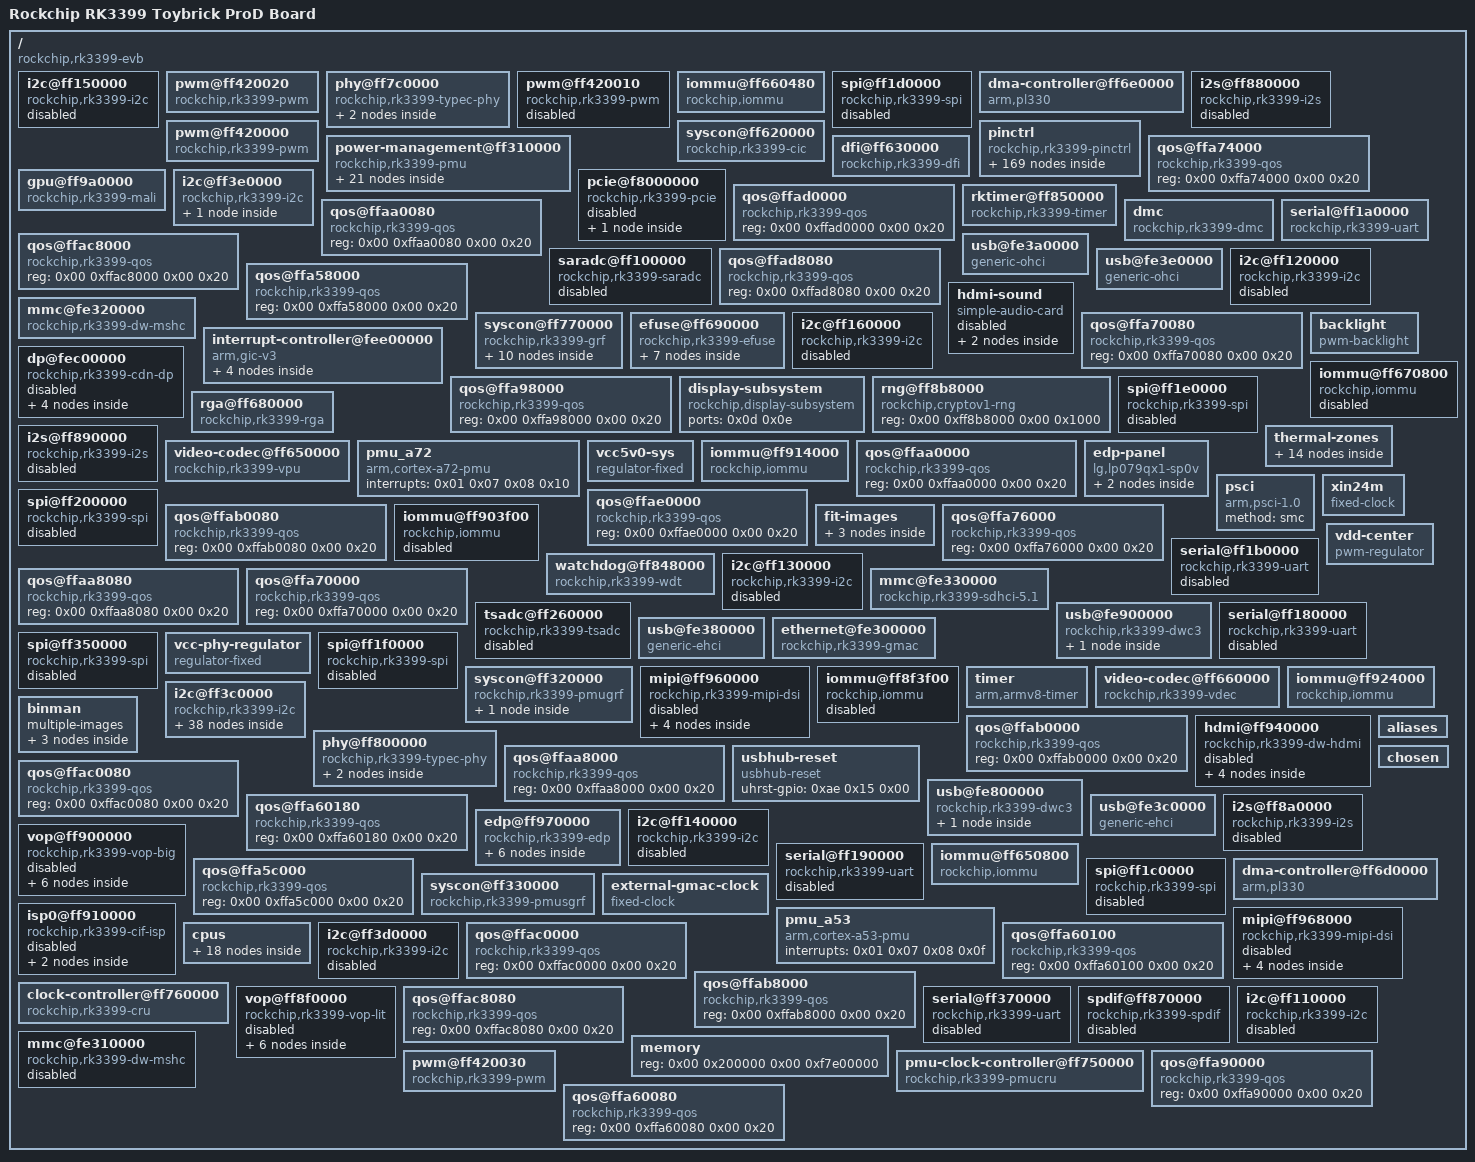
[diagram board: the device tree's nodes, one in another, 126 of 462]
/dts-v1/;

/ {
	#address-cells = <0x02>;
	model = "Rockchip RK3399 Toybrick ProD Board";
	#size-cells = <0x02>;
	interrupt-parent = <0x01>;
	compatible = "rockchip,rk3399-evb\0rockchip,rk3399";

	i2c@ff150000 {
		pinctrl-names = "default";
		#address-cells = <0x01>;
		pinctrl-0 = <0x32>;
		clock-names = "i2c\0pclk";
		assigned-clocks = <0x08 0x45>;
		assigned-clock-rates = <0xbebc200>;
		interrupts = <0x00 0x25 0x04 0x00>;
		clocks = <0x08 0x45 0x08 0x159>;
		#size-cells = <0x00>;
		compatible = "rockchip,rk3399-i2c";
		status = "disabled";
		reg = <0x00 0xff150000 0x00 0x1000>;
	};

	pwm@ff420020 {
		pinctrl-names = "default";
		pinctrl-0 = <0x7d>;
		clocks = <0x6a 0x1e>;
		#pwm-cells = <0x03>;
		compatible = "rockchip,rk3399-pwm\0rockchip,rk3288-pwm";
		status = "okay";
		reg = <0x00 0xff420020 0x00 0x10>;
	};

	phy@ff7c0000 {
		power-domains = <0x16 0x08>;
		clock-names = "tcpdcore\0tcpdphy-ref";
		assigned-clocks = <0x08 0x7e>;
		assigned-clock-rates = <0x2faf080>;
		resets = <0x08 0x95 0x08 0x94 0x08 0x14c>;
		clocks = <0x08 0x7e 0x08 0x7d>;
		extcon = <0x24>;
		compatible = "rockchip,rk3399-typec-phy";
		status = "okay";
		rockchip,grf = <0x17>;
		reg = <0x00 0xff7c0000 0x00 0x40000>;
		reset-names = "uphy\0uphy-pipe\0uphy-tcphy";

		dp-port {
			#phy-cells = <0x00>;
			phandle = <0x2a>;
		};

		usb3-port {
			#phy-cells = <0x00>;
			phandle = <0x26>;
		};
	};

	pwm@ff420010 {
		pinctrl-names = "default";
		pinctrl-0 = <0x7c>;
		clocks = <0x6a 0x1e>;
		#pwm-cells = <0x03>;
		compatible = "rockchip,rk3399-pwm\0rockchip,rk3288-pwm";
		status = "disabled";
		reg = <0x00 0xff420010 0x00 0x10>;
	};

	iommu@ff660480 {
		power-domains = <0x16 0x20>;
		clock-names = "aclk\0iface";
		interrupts = <0x00 0x75 0x04 0x00>;
		clocks = <0x08 0xed 0x08 0x1ec>;
		#iommu-cells = <0x00>;
		compatible = "rockchip,iommu";
		interrupt-names = "vdec_mmu";
		reg = <0x00 0xff660480 0x00 0x40 0x00 0xff6604c0 0x00 0x40>;
		phandle = <0x80>;
	};

	spi@ff1d0000 {
		pinctrl-names = "default";
		#address-cells = <0x01>;
		pinctrl-0 = <0x3d 0x3e 0x3f 0x40>;
		clock-names = "spiclk\0apb_pclk";
		u-boot,dm-pre-reloc;
		interrupts = <0x00 0x35 0x04 0x00>;
		clocks = <0x08 0x48 0x08 0x15c>;
		#size-cells = <0x00>;
		dma-names = "tx\0rx";
		compatible = "rockchip,rk3399-spi\0rockchip,rk3066-spi";
		status = "disabled";
		reg = <0x00 0xff1d0000 0x00 0x1000>;
		dmas = <0x38 0x0c 0x38 0x0d>;
	};

	dma-controller@ff6e0000 {
		clock-names = "apb_pclk";
		interrupts = <0x00 0x07 0x04 0x00 0x00 0x08 0x04 0x00>;
		clocks = <0x08 0xd4>;
		arm,pl330-periph-burst;
		compatible = "arm,pl330\0arm,primecell";
		reg = <0x00 0xff6e0000 0x00 0x4000>;
		phandle = <0x38>;
		#dma-cells = <0x01>;
	};

	i2s@ff880000 {
		power-domains = <0x16 0x1c>;
		pinctrl-names = "default";
		pinctrl-0 = <0x85>;
		clock-names = "i2s_clk\0i2s_hclk";
		interrupts = <0x00 0x27 0x04 0x00>;
		clocks = <0x08 0x56 0x08 0x1d4>;
		dma-names = "tx\0rx";
		#sound-dai-cells = <0x00>;
		compatible = "rockchip,rk3399-i2s\0rockchip,rk3066-i2s";
		status = "disabled";
		rockchip,grf = <0x17>;
		reg = <0x00 0xff880000 0x00 0x1000>;
		dmas = <0x49 0x00 0x49 0x01>;
	};

	pwm@ff420000 {
		pinctrl-names = "default";
		pinctrl-0 = <0x7b>;
		clocks = <0x6a 0x1e>;
		#pwm-cells = <0x03>;
		compatible = "rockchip,rk3399-pwm\0rockchip,rk3288-pwm";
		status = "okay";
		reg = <0x00 0xff420000 0x00 0x10>;
		phandle = <0xa9>;
	};

	pinctrl {
		pinctrl-names = "default";
		#address-cells = <0x02>;
		pinctrl-0 = <0xa2>;
		u-boot,dm-pre-reloc;
		#size-cells = <0x02>;
		compatible = "rockchip,rk3399-pinctrl";
		rockchip,pmu = <0x81>;
		ranges;
		rockchip,grf = <0x17>;

		i2c3 {

			i2c3-xfer {
				rockchip,pins = <0x04 0x11 0x01 0xa3 0x04 0x10 0x01 0xa3>;
				phandle = <0x30>;
			};
		};

		leds-gpio {
			rockchip,pins = <0x02 0x05 0x00 0xa6 0x02 0x04 0x00 0xa6 0x02 0x03 0x00 0xa6>;
		};

		clock {

			clk-32k {
				rockchip,pins = <0x00 0x00 0x02 0xa3>;
			};
		};

		spi2 {

			spi2-clk {
				rockchip,pins = <0x02 0x0b 0x01 0xa6>;
				phandle = <0x41>;
			};

			spi2-cs0 {
				rockchip,pins = <0x02 0x0c 0x01 0xa6>;
				phandle = <0x44>;
			};

			spi2-tx {
				rockchip,pins = <0x02 0x0a 0x01 0xa6>;
				phandle = <0x42>;
			};

			spi2-rx {
				rockchip,pins = <0x02 0x09 0x01 0xa6>;
				phandle = <0x43>;
			};
		};

		pcfg-pull-none-12ma {
			drive-strength = <0x0c>;
			bias-disable;
			phandle = <0xa5>;
		};

		pcfg-pull-up-20ma {
			drive-strength = <0x14>;
			bias-pull-up;
		};

		i2s1 {

			i2s1-2ch-bus {
				rockchip,pins = <0x04 0x03 0x01 0xa3 0x04 0x04 0x01 0xa3 0x04 0x05 0x01 0xa3 0x04 0x06 0x01 0xa3 0x04 0x07 0x01 0xa3>;
				phandle = <0x86>;
			};
		};

		i2c1 {

			i2c1-xfer {
				rockchip,pins = <0x04 0x02 0x01 0xa3 0x04 0x01 0x01 0xa3>;
				phandle = <0x2e>;
			};
		};

		gmac {

			rmii-pins {
				rockchip,pins = <0x03 0x0d 0x01 0xa3 0x03 0x0c 0x01 0xa4 0x03 0x0b 0x01 0xa3 0x03 0x0a 0x01 0xa3 0x03 0x09 0x01 0xa3 0x03 0x08 0x01 0xa3 0x03 0x07 0x01 0xa3 0x03 0x06 0x01 0xa3 0x03 0x05 0x01 0xa4 0x03 0x04 0x01 0xa4>;
			};

			rgmii-pins {
				rockchip,pins = <0x03 0x11 0x01 0xa4 0x03 0x0e 0x01 0xa3 0x03 0x0d 0x01 0xa3 0x03 0x0c 0x01 0xa4 0x03 0x0b 0x01 0xa3 0x03 0x09 0x01 0xa3 0x03 0x08 0x01 0xa3 0x03 0x07 0x01 0xa3 0x03 0x06 0x01 0xa3 0x03 0x05 0x01 0xa4 0x03 0x04 0x01 0xa4 0x03 0x03 0x01 0xa3 0x03 0x02 0x01 0xa3 0x03 0x01 0x01 0xa4 0x03 0x00 0x01 0xa4>;
				phandle = <0x1a>;
			};
		};

		usb3 {

			hub-rst {
				rockchip,pins = <0x04 0x15 0x00 0xa6>;
			};

			usb3-host-en {
				rockchip,pins = <0x02 0x02 0x00 0xa6>;
				phandle = <0x27>;
			};
		};

		spi0 {

			spi0-tx {
				rockchip,pins = <0x03 0x05 0x02 0xa6>;
				phandle = <0x3a>;
			};

			spi0-rx {
				rockchip,pins = <0x03 0x04 0x02 0xa6>;
				phandle = <0x3b>;
			};

			spi0-cs1 {
				rockchip,pins = <0x03 0x08 0x02 0xa6>;
			};

			spi0-clk {
				rockchip,pins = <0x03 0x06 0x02 0xa6>;
				phandle = <0x39>;
			};

			spi0-cs0 {
				rockchip,pins = <0x03 0x07 0x02 0xa6>;
				phandle = <0x3c>;
			};
		};

		gpio4@ff790000 {
			gpio-controller;
			interrupts = <0x00 0x12 0x04 0x00>;
			clocks = <0x08 0x152>;
			compatible = "rockchip,gpio-bank";
			#interrupt-cells = <0x02>;
			reg = <0x00 0xff790000 0x00 0x100>;
			phandle = <0xae>;
			#gpio-cells = <0x02>;
			interrupt-controller;
		};

		pcfg-pull-down-4ma {
			drive-strength = <0x04>;
			bias-pull-down;
		};

		pcfg-pull-down {
			bias-pull-down;
			phandle = <0xa7>;
		};

		uart4 {

			uart4-xfer {
				rockchip,pins = <0x01 0x07 0x01 0xa6 0x01 0x08 0x01 0xa3>;
				phandle = <0x6f>;
			};
		};

		pcfg-pull-none-18ma {
			drive-strength = <0x12>;
			bias-disable;
		};

		i2c8 {

			i2c8-xfer {
				rockchip,pins = <0x01 0x15 0x01 0xa3 0x01 0x14 0x01 0xa3>;
				phandle = <0x79>;
			};
		};

		pcfg-pull-none-20ma {
			drive-strength = <0x14>;
			bias-disable;
		};

		i2c6 {

			i2c6-xfer {
				rockchip,pins = <0x02 0x0a 0x02 0xa3 0x02 0x09 0x02 0xa3>;
				phandle = <0x32>;
			};
		};

		uarthdcp {

			uarthdcp-xfer {
				rockchip,pins = <0x04 0x15 0x02 0xa6 0x04 0x16 0x02 0xa3>;
			};
		};

		pwm1 {

			pwm1-pin {
				rockchip,pins = <0x04 0x16 0x01 0xa3>;
				phandle = <0x7c>;
			};

			pwm1-pin-pull-down {
				rockchip,pins = <0x04 0x16 0x01 0xa7>;
			};
		};

		uart2b {

			uart2b-xfer {
				rockchip,pins = <0x04 0x10 0x02 0xa6 0x04 0x11 0x02 0xa3>;
			};
		};

		edp {

			edp-hpd {
				rockchip,pins = <0x04 0x17 0x02 0xa3>;
				phandle = <0x9d>;
			};
		};

		spi5 {

			spi5-cs0 {
				rockchip,pins = <0x02 0x17 0x02 0xa6>;
				phandle = <0x4d>;
			};

			spi5-tx {
				rockchip,pins = <0x02 0x15 0x02 0xa6>;
				phandle = <0x4b>;
			};

			spi5-rx {
				rockchip,pins = <0x02 0x14 0x02 0xa6>;
				phandle = <0x4c>;
			};

			spi5-clk {
				rockchip,pins = <0x02 0x16 0x02 0xa6>;
				phandle = <0x4a>;
			};
		};

		tsadc {

			otp-pin {
				rockchip,pins = <0x01 0x06 0x00 0xa3>;
				phandle = <0x53>;
			};

			otp-out {
				rockchip,pins = <0x01 0x06 0x01 0xa3>;
				phandle = <0x54>;
			};
		};

		uart0 {

			uart0-cts {
				rockchip,pins = <0x02 0x12 0x01 0xa3>;
			};

			uart0-rts {
				rockchip,pins = <0x02 0x13 0x01 0xa3>;
			};

			uart0-xfer {
				rockchip,pins = <0x02 0x10 0x01 0xa6 0x02 0x11 0x01 0xa3>;
				phandle = <0x34>;
			};
		};

		i2c4 {

			i2c4-xfer {
				rockchip,pins = <0x01 0x0c 0x01 0xa3 0x01 0x0b 0x01 0xa3>;
				phandle = <0x78>;
			};
		};

		pcfg-pull-down-12ma {
			drive-strength = <0x0c>;
			bias-pull-down;
		};

		gpio2@ff780000 {
			gpio-controller;
			interrupts = <0x00 0x10 0x04 0x00>;
			clocks = <0x08 0x150>;
			compatible = "rockchip,gpio-bank";
			#interrupt-cells = <0x02>;
			reg = <0x00 0xff780000 0x00 0x100>;
			#gpio-cells = <0x02>;
			interrupt-controller;
		};

		spdif {

			spdif-bus-1 {
				rockchip,pins = <0x03 0x10 0x03 0xa3>;
			};

			spdif-bus {
				rockchip,pins = <0x04 0x15 0x01 0xa3>;
				phandle = <0x84>;
			};
		};

		gpio0@ff720000 {
			gpio-controller;
			interrupts = <0x00 0x0e 0x04 0x00>;
			clocks = <0x6a 0x17>;
			compatible = "rockchip,gpio-bank";
			#interrupt-cells = <0x02>;
			reg = <0x00 0xff720000 0x00 0x100>;
			phandle = <0x1b>;
			#gpio-cells = <0x02>;
			interrupt-controller;
		};

		pcfg-output-high {
			output-high;
		};

		pcie {

			pci-clkreqn-cpm {
				rockchip,pins = <0x02 0x1a 0x00 0xa3>;
				phandle = <0x15>;
			};

			pci-clkreqnb-cpm {
				rockchip,pins = <0x04 0x18 0x00 0xa3>;
			};
		};

		pcfg-pull-up {
			phandle = <0xa6>;
			bias-pull-up;
		};

		spi3 {

			spi3-tx {
				rockchip,pins = <0x01 0x10 0x01 0xa6>;
				phandle = <0x6c>;
			};

			spi3-rx {
				rockchip,pins = <0x01 0x0f 0x01 0xa6>;
				phandle = <0x6d>;
			};

			spi3-clk {
				rockchip,pins = <0x01 0x11 0x01 0xa6>;
				phandle = <0x6b>;
			};

			spi3-cs0 {
				rockchip,pins = <0x01 0x12 0x01 0xa6>;
				phandle = <0x6e>;
			};
		};

		pwm3a {

			pwm3a-pin {
				rockchip,pins = <0x00 0x06 0x01 0xa3>;
				phandle = <0x7e>;
			};
		};

		sdio0 {

			sdio0-clk {
				rockchip,pins = <0x02 0x19 0x01 0xa3>;
			};

			sdio0-wp {
				rockchip,pins = <0x00 0x03 0x01 0xa6>;
			};

			sdio0-bus4 {
				rockchip,pins = <0x02 0x14 0x01 0xa6 0x02 0x15 0x01 0xa6 0x02 0x16 0x01 0xa6 0x02 0x17 0x01 0xa6>;
			};

			sdio0-bkpwr {
				rockchip,pins = <0x02 0x1c 0x01 0xa6>;
			};

			sdio0-cd {
				rockchip,pins = <0x02 0x1a 0x01 0xa6>;
			};

			sdio0-pwr {
				rockchip,pins = <0x02 0x1b 0x01 0xa6>;
			};

			sdio0-int {
				rockchip,pins = <0x00 0x04 0x01 0xa6>;
			};

			sdio0-bus1 {
				rockchip,pins = <0x02 0x14 0x01 0xa6>;
			};

			sdio0-cmd {
				rockchip,pins = <0x02 0x18 0x01 0xa6>;
			};
		};

		pcfg-pull-up-2ma {
			drive-strength = <0x02>;
			bias-pull-up;
		};

		i2c2 {

			i2c2-xfer {
				rockchip,pins = <0x02 0x01 0x02 0xa5 0x02 0x00 0x02 0xa5>;
				phandle = <0x2f>;
			};
		};

		pmic {

			soc-slppin-slp {
				rockchip,pins = <0x01 0x05 0x01 0xa7>;
			};

			vsel2-gpio {
				rockchip,pins = <0x01 0x0e 0x00 0xa7>;
				phandle = <0x77>;
			};

			vsel1-gpio {
				rockchip,pins = <0x01 0x11 0x00 0xa7>;
				phandle = <0x76>;
			};

			soc-slppin-gpio {
				rockchip,pins = <0x01 0x05 0x00 0xa8>;
			};

			pmic-int-l {
				rockchip,pins = <0x01 0x12 0x00 0xa6>;
				phandle = <0x72>;
			};
		};

		pcfg-pull-none {
			bias-disable;
			phandle = <0xa3>;
		};

		spi1 {

			spi1-cs0 {
				rockchip,pins = <0x01 0x0a 0x02 0xa6>;
				phandle = <0x40>;
			};

			spi1-clk {
				rockchip,pins = <0x01 0x09 0x02 0xa6>;
				phandle = <0x3d>;
			};

			spi1-tx {
				rockchip,pins = <0x01 0x08 0x02 0xa6>;
				phandle = <0x3e>;
			};

			spi1-rx {
				rockchip,pins = <0x01 0x07 0x02 0xa6>;
				phandle = <0x3f>;
			};
		};

		pcfg-pull-down-18ma {
			drive-strength = <0x12>;
			bias-pull-down;
		};

		sdmmc {

			sdmmc-wp {
				rockchip,pins = <0x00 0x08 0x01 0xa6>;
			};

			sdmmc-bus1 {
				rockchip,pins = <0x04 0x08 0x01 0xa6>;
			};

			sdmmc-cd {
				rockchip,pins = <0x00 0x07 0x01 0xa6>;
			};

			sdmmc-bus4 {
				rockchip,pins = <0x04 0x08 0x01 0xa6 0x04 0x09 0x01 0xa6 0x04 0x0a 0x01 0xa6 0x04 0x0b 0x01 0xa6>;
				phandle = <0x1e>;
			};

			sdmmc-cmd {
				rockchip,pins = <0x04 0x0d 0x01 0xa6>;
				phandle = <0x1d>;
			};

			sdmmc-clk {
				rockchip,pins = <0x04 0x0c 0x01 0xa3>;
				phandle = <0x1c>;
			};
		};

		i2s0 {

			i2s0-8ch-bus {
				rockchip,pins = <0x03 0x18 0x01 0xa3 0x03 0x19 0x01 0xa3 0x03 0x1a 0x01 0xa3 0x03 0x1b 0x01 0xa3 0x03 0x1c 0x01 0xa3 0x03 0x1d 0x01 0xa3 0x03 0x1e 0x01 0xa3 0x03 0x1f 0x01 0xa3 0x04 0x00 0x01 0xa3>;
				phandle = <0x85>;
			};

			i2s0-2ch-bus {
				rockchip,pins = <0x03 0x18 0x01 0xa3 0x03 0x19 0x01 0xa3 0x03 0x1a 0x01 0xa3 0x03 0x1b 0x01 0xa3 0x03 0x1f 0x01 0xa3 0x04 0x00 0x01 0xa3>;
			};
		};

		i2c0 {

			i2c0-xfer {
				rockchip,pins = <0x01 0x0f 0x02 0xa3 0x01 0x10 0x02 0xa3>;
				phandle = <0x70>;
			};
		};

		suspend {

			ap-pwroff {
				rockchip,pins = <0x01 0x05 0x01 0xa3>;
			};

			ddrio-pwroff {
				rockchip,pins = <0x00 0x01 0x01 0xa3>;
			};
		};

		testclk {

			test-clkout2 {
				rockchip,pins = <0x00 0x08 0x03 0xa3>;
			};

			test-clkout0 {
				rockchip,pins = <0x00 0x00 0x01 0xa3>;
			};

			test-clkout1 {
				rockchip,pins = <0x02 0x19 0x02 0xa3>;
			};
		};

		pcfg-pull-up-8ma {
			drive-strength = <0x08>;
			bias-pull-up;
		};

		pcfg-pull-down-20ma {
			drive-strength = <0x14>;
			bias-pull-down;
		};

		npu_clk {

			npu-ref-clk {
				rockchip,pins = <0x00 0x02 0x01 0xa3>;
				phandle = <0xa2>;
			};
		};

		pcfg-pull-none-13ma {
			drive-strength = <0x0d>;
			bias-disable;
			phandle = <0xa4>;
		};

		fusb30x {

			fusb0-int {
				rockchip,pins = <0x01 0x02 0x00 0xa6>;
				phandle = <0x7a>;
			};
		};

		uart3 {

			uart3-cts {
				rockchip,pins = <0x03 0x10 0x02 0xa3>;
			};

			uart3-rts {
				rockchip,pins = <0x03 0x11 0x02 0xa3>;
			};

			uart3-xfer {
				rockchip,pins = <0x03 0x0e 0x02 0xa6 0x03 0x0f 0x02 0xa3>;
				phandle = <0x37>;
			};
		};

		pcfg-output-low {
			phandle = <0xa8>;
			output-low;
		};

		i2c7 {

			i2c7-xfer {
				rockchip,pins = <0x02 0x08 0x02 0xa3 0x02 0x07 0x02 0xa3>;
				phandle = <0x33>;
			};
		};

		pwm2 {

			pwm2-pin {
				rockchip,pins = <0x01 0x13 0x01 0xa3>;
				phandle = <0x7d>;
			};

			pwm2-pin-pull-down {
				rockchip,pins = <0x01 0x13 0x01 0xa7>;
			};
		};

		uart2c {

			uart2c-xfer {
				rockchip,pins = <0x04 0x13 0x01 0xa6 0x04 0x14 0x01 0xa3>;
				phandle = <0x36>;
			};
		};

		uart1 {

			uart1-xfer {
				rockchip,pins = <0x03 0x0c 0x02 0xa6 0x03 0x0d 0x02 0xa3>;
				phandle = <0x35>;
			};
		};

		hdmi {

			hdmi-i2c-xfer {
				rockchip,pins = <0x04 0x11 0x03 0xa3 0x04 0x10 0x03 0xa3>;
			};

			hdmi-cec {
				rockchip,pins = <0x04 0x17 0x01 0xa3>;
			};
		};

		i2c5 {

			i2c5-xfer {
				rockchip,pins = <0x03 0x0b 0x02 0xa3 0x03 0x0a 0x02 0xa3>;
				phandle = <0x31>;
			};
		};

		pwm0 {

			pwm0-pin-pull-down {
				rockchip,pins = <0x04 0x12 0x01 0xa7>;
			};

			vop1-pwm-pin {
				rockchip,pins = <0x04 0x12 0x03 0xa3>;
			};

			vop0-pwm-pin {
				rockchip,pins = <0x04 0x12 0x02 0xa3>;
			};

			pwm0-pin {
				rockchip,pins = <0x04 0x12 0x01 0xa3>;
				phandle = <0x7b>;
			};
		};

		uart2a {

			uart2a-xfer {
				rockchip,pins = <0x04 0x08 0x02 0xa6 0x04 0x09 0x02 0xa3>;
			};
		};

		spi4 {

			spi4-clk {
				rockchip,pins = <0x03 0x02 0x02 0xa6>;
				phandle = <0x45>;
			};

			spi4-tx {
				rockchip,pins = <0x03 0x01 0x02 0xa6>;
				phandle = <0x46>;
			};

			spi4-rx {
				rockchip,pins = <0x03 0x00 0x02 0xa6>;
				phandle = <0x47>;
			};

			spi4-cs0 {
				rockchip,pins = <0x03 0x03 0x02 0xa6>;
				phandle = <0x48>;
			};
		};

		pcfg-pull-down-8ma {
			drive-strength = <0x08>;
			bias-pull-down;
		};

		gpio1@ff730000 {
			gpio-controller;
			interrupts = <0x00 0x0f 0x04 0x00>;
			clocks = <0x6a 0x18>;
			compatible = "rockchip,gpio-bank";
			#interrupt-cells = <0x02>;
			reg = <0x00 0xff730000 0x00 0x100>;
			phandle = <0x71>;
			#gpio-cells = <0x02>;
			interrupt-controller;
		};

		pwm3b {

			pwm3b-pin {
				rockchip,pins = <0x01 0x0e 0x01 0xa3>;
			};
		};

		gpio3@ff788000 {
			gpio-controller;
			interrupts = <0x00 0x11 0x04 0x00>;
			clocks = <0x08 0x151>;
			compatible = "rockchip,gpio-bank";
			#interrupt-cells = <0x02>;
			reg = <0x00 0xff788000 0x00 0x100>;
			phandle = <0x14>;
			#gpio-cells = <0x02>;
			interrupt-controller;
		};

		pcfg-pull-up-18ma {
			drive-strength = <0x12>;
			bias-pull-up;
		};
	};

	power-management@ff310000 {
		u-boot,dm-pre-reloc;
		compatible = "rockchip,rk3399-pmu\0syscon\0simple-mfd";
		reg = <0x00 0xff310000 0x00 0x1000>;

		power-controller {
			#address-cells = <0x01>;
			#size-cells = <0x00>;
			#power-domain-cells = <0x01>;
			compatible = "rockchip,rk3399-power-controller";
			phandle = <0x16>;

			power-domain@9 {
				clocks = <0x08 0x80 0x08 0x7f>;
				#power-domain-cells = <0x00>;
				reg = <0x09>;
			};

			power-domain@27 {
				clocks = <0x08 0x1ce 0x08 0x4c>;
				#power-domain-cells = <0x00>;
				reg = <0x1b>;
				pm_qos = <0x5e>;
			};

			power-domain@35 {
				clocks = <0x08 0xd0>;
				#power-domain-cells = <0x00>;
				reg = <0x23>;
				pm_qos = <0x5b>;
			};

			power-domain@25 {
				clocks = <0x08 0x16c>;
				#power-domain-cells = <0x00>;
				reg = <0x19>;
			};

			power-domain@15 {
				#address-cells = <0x01>;
				#size-cells = <0x00>;
				#power-domain-cells = <0x01>;
				reg = <0x0f>;

				power-domain@19 {
					clocks = <0x08 0xe5 0x08 0x1df>;
					#power-domain-cells = <0x00>;
					reg = <0x13>;
					pm_qos = <0x63 0x64>;
				};

				power-domain@21 {
					clocks = <0x08 0xde 0x08 0x1e7 0x08 0x172>;
					#power-domain-cells = <0x00>;
					reg = <0x15>;
					pm_qos = <0x62>;
				};

				power-domain@16 {
					#address-cells = <0x01>;
					#size-cells = <0x00>;
					#power-domain-cells = <0x01>;
					reg = <0x10>;

					power-domain@17 {
						clocks = <0x08 0xd9 0x08 0x1d9>;
						#power-domain-cells = <0x00>;
						reg = <0x11>;
						pm_qos = <0x67 0x68>;
					};

					power-domain@18 {
						clocks = <0x08 0xdb 0x08 0x1db>;
						#power-domain-cells = <0x00>;
						reg = <0x12>;
						pm_qos = <0x69>;
					};
				};

				power-domain@20 {
					clocks = <0x08 0xe6 0x08 0x1e0>;
					#power-domain-cells = <0x00>;
					reg = <0x14>;
					pm_qos = <0x65 0x66>;
				};
			};

			power-domain@33 {
				clocks = <0x08 0xdc 0x08 0x1e5>;
				#power-domain-cells = <0x00>;
				reg = <0x21>;
				pm_qos = <0x56 0x57>;
			};

			power-domain@23 {
				clocks = <0x08 0xf0>;
				#power-domain-cells = <0x00>;
				reg = <0x17>;
				pm_qos = <0x5c>;
			};

			power-domain@31 {
				clocks = <0x08 0xeb 0x08 0x1ea>;
				#power-domain-cells = <0x00>;
				reg = <0x1f>;
				pm_qos = <0x58>;
			};

			power-domain@28 {
				clocks = <0x08 0x1ee>;
				#power-domain-cells = <0x00>;
				reg = <0x1c>;
				pm_qos = <0x5f>;
			};

			power-domain@8 {
				clocks = <0x08 0x7e 0x08 0x7d>;
				#power-domain-cells = <0x00>;
				reg = <0x08>;
			};

			power-domain@34 {
				clocks = <0x08 0xe1 0x08 0x1dd>;
				#power-domain-cells = <0x00>;
				reg = <0x22>;
				pm_qos = <0x55>;
			};

			power-domain@24 {
				clocks = <0x08 0xf4>;
				#power-domain-cells = <0x00>;
				reg = <0x18>;
				pm_qos = <0x60 0x61>;
			};

			power-domain@32 {
				clocks = <0x08 0xed 0x08 0x1ec>;
				#power-domain-cells = <0x00>;
				reg = <0x20>;
				pm_qos = <0x59 0x5a>;
			};

			power-domain@22 {
				clocks = <0x08 0xd5 0x08 0x166>;
				#power-domain-cells = <0x00>;
				reg = <0x16>;
				pm_qos = <0x5d>;
			};
		};
	};

	syscon@ff620000 {
		u-boot,dm-pre-reloc;
		compatible = "rockchip,rk3399-cic\0syscon";
		reg = <0x00 0xff620000 0x00 0x100>;
	};

	qos@ffa74000 {
		compatible = "rockchip,rk3399-qos\0syscon";
		reg = <0x00 0xffa74000 0x00 0x20>;
		phandle = <0x5e>;
	};

	gpu@ff9a0000 {
		power-domains = <0x16 0x23>;
		mali-supply = <0xa1>;
		interrupts = <0x00 0x14 0x04 0x00 0x00 0x15 0x04 0x00 0x00 0x13 0x04 0x00>;
		clocks = <0x08 0xd0>;
		compatible = "rockchip,rk3399-mali\0arm,mali-t860";
		status = "okay";
		interrupt-names = "job\0mmu\0gpu";
		reg = <0x00 0xff9a0000 0x00 0x10000>;
		phandle = <0x52>;
		#cooling-cells = <0x02>;
	};

	dfi@ff630000 {
		clock-names = "pclk_ddr_mon";
		u-boot,dm-pre-reloc;
		clocks = <0x08 0x179>;
		compatible = "rockchip,rk3399-dfi";
		rockchip,pmu = <0x81>;
		reg = <0x00 0xff630000 0x00 0x4000>;
		phandle = <0xaf>;
	};

	i2c@ff3e0000 {
		pinctrl-names = "default";
		#address-cells = <0x01>;
		pinctrl-0 = <0x79>;
		clock-names = "i2c\0pclk";
		assigned-clocks = <0x6a 0x0b>;
		i2c-scl-rising-time-ns = <0x159>;
		i2c-scl-falling-time-ns = <0x0b>;
		assigned-clock-rates = <0xbebc200>;
		interrupts = <0x00 0x3a 0x04 0x00>;
		clocks = <0x6a 0x0b 0x6a 0x1d>;
		#size-cells = <0x00>;
		clock-frequency = <0x186a0>;
		compatible = "rockchip,rk3399-i2c";
		status = "okay";
		reg = <0x00 0xff3e0000 0x00 0x1000>;

		fusb30x@22 {
			pinctrl-names = "default";
			pinctrl-0 = <0x7a>;
			int-n-gpios = <0x71 0x02 0x00>;
			vbus-5v-gpios = <0x1b 0x01 0x01>;
			compatible = "fairchild,fusb302";
			status = "okay";
			reg = <0x22>;
			phandle = <0x24>;
		};
	};

	pcie@f8000000 {
		pinctrl-names = "default";
		#address-cells = <0x03>;
		phy-names = "pcie-phy-0\0pcie-phy-1\0pcie-phy-2\0pcie-phy-3";
		bus-range = <0x00 0x1f>;
		pinctrl-0 = <0x15>;
		clock-names = "aclk\0aclk-perf\0hclk\0pm";
		reg-names = "axi-base\0apb-base";
		ep-gpios = <0x14 0x0d 0x00>;
		resets = <0x08 0x82 0x08 0x83 0x08 0x84 0x08 0x85 0x08 0x86 0x08 0x81 0x08 0x80>;
		interrupts = <0x00 0x31 0x04 0x00 0x00 0x32 0x04 0x00 0x00 0x33 0x04 0x00>;
		clocks = <0x08 0xc5 0x08 0xc4 0x08 0x147 0x08 0xa0>;
		interrupt-map = <0x00 0x00 0x00 0x01 0x11 0x00 0x00 0x00 0x00 0x02 0x11 0x01 0x00 0x00 0x00 0x03 0x11 0x02 0x00 0x00 0x00 0x04 0x11 0x03>;
		#size-cells = <0x02>;
		aspm-no-l0s;
		max-link-speed = <0x01>;
		device_type = "pci";
		interrupt-map-mask = <0x00 0x00 0x00 0x07>;
		num-lanes = <0x04>;
		compatible = "rockchip,rk3399-pcie";
		ranges = <0x82000000 0x00 0xfa000000 0x00 0xfa000000 0x00 0x1e00000 0x81000000 0x00 0xfbe00000 0x00 0xfbe00000 0x00 0x100000>;
		msi-map = <0x00 0x12 0x00 0x1000>;
		#interrupt-cells = <0x01>;
		status = "disabled";
		interrupt-names = "sys\0legacy\0client";
		phys = <0x13 0x00 0x13 0x01 0x13 0x02 0x13 0x03>;
		reg = <0x00 0xf8000000 0x00 0x2000000 0x00 0xfd000000 0x00 0x1000000>;
		reset-names = "core\0mgmt\0mgmt-sticky\0pipe\0pm\0pclk\0aclk";

		interrupt-controller {
			#address-cells = <0x00>;
			#interrupt-cells = <0x01>;
			phandle = <0x11>;
			interrupt-controller;
		};
	};

	qos@ffad0000 {
		compatible = "rockchip,rk3399-qos\0syscon";
		reg = <0x00 0xffad0000 0x00 0x20>;
		phandle = <0x69>;
	};

	rktimer@ff850000 {
		clock-names = "pclk\0timer";
		interrupts = <0x00 0x51 0x04 0x00>;
		clocks = <0x08 0x168 0x08 0x5a>;
		compatible = "rockchip,rk3399-timer";
		reg = <0x00 0xff850000 0x00 0x1000>;
	};

	qos@ffaa0080 {
		compatible = "rockchip,rk3399-qos\0syscon";
		reg = <0x00 0xffaa0080 0x00 0x20>;
		phandle = <0x64>;
	};

	dmc {
		clock-names = "dmc_clk";
		u-boot,dm-pre-reloc;
		interrupts = <0x00 0x01 0x04 0x00>;
		clocks = <0x08 0xaa>;
		devfreq-events = <0xaf>;
		compatible = "rockchip,rk3399-dmc";
		rockchip,sdram-params = <0x02 0x0a 0x03 0x02 0x02 0x00 0x0f 0x0f 0x0f 0x0f 0x01 0x1d191519 0x14040808 0x02 0x6226 0x54 0x00 0x02 0x0a 0x03 0x02 0x02 0x00 0x0f 0x0f 0x0f 0x0f 0x01 0x1d191519 0x14040808 0x02 0x6226 0x54 0x00 0x320 0x06 0x02 0x0d 0x01 0x700 0x00 0x00 0x00 0x00 0x50 0x27100 0x320 0x1f40 0x50 0x27100 0x320 0x1f40 0x50 0x27100 0x320 0x1001f40 0x00 0x101 0x20100 0xa0 0x190 0x00 0x6180000 0x61800 0x4000618 0x33080004 0x280f0622 0x22330800 0x280f06 0x6223308 0x600280f 0xa0a 0x600dac0 0xa0a060c 0x600dac0 0xa0a060c 0x600dac0 0x203000c 0xf0c0f00 0x40c0f0c 0x14000a0a 0x3030a0a 0x10003 0x31b1b1b 0x111111 0x00 0x3010000 0xc2800a8 0xc2800a8 0xc2800a8 0x00 0x60006 0x140006 0x140014 0xf0f0f 0x00 0x00 0x00 0xb00000 0xb000b0 0xb000b0 0xb0 0x00 0x00 0x00 0x00 0x00 0x00 0x301 0x01 0x00 0x00 0x1000000 0x80104002 0x40003 0x40005 0x30000 0x50004 0x04 0x40003 0x40005 0x30a00000 0x1850 0x185030a0 0x30a00000 0x1850 0x00 0x00 0x00 0x00 0x00 0x2020200 0x20202 0x30200 0x40700 0x302 0x2000407 0x03 0x30f04 0x70004 0x00 0x00 0x00 0x00 0x00 0x00 0x00 0x10000 0x20040020 0x200400 0x1000400 0xb80 0x00 0x01 0x02 0x0e 0x00 0x00 0x00 0x00 0x00 0xa00000 0xc80050 0xc80000 0x5000a0 0xc8 0xa000c8 0xc80050 0xc80000 0x00 0x00 0x00 0x430000 0x1a 0x1a0043 0x430000 0x1a 0x10001 0x7000001 0x707 0x00 0x00 0x00 0x00 0x00 0x00 0x430000 0x1a 0x1a0043 0x430000 0x1a 0x10001 0x7000001 0x707 0x00 0x00 0x00 0x00 0x00 0x00 0x1000000 0x00 0x00 0x18151100 0x0c 0x00 0x00 0x00 0x00 0x00 0x00 0x00 0x00 0x00 0x00 0x00 0x00 0x00 0x32003 0x480120 0x00 0x1200320 0x48 0x32000 0x480120 0x00 0x280000 0x280028 0x1010100 0x1000202 0xa000002 0x1000f0f 0x00 0x00 0x10003 0xc03 0x100 0x10000 0x1000000 0x10000 0x01 0x00 0x00 0x00 0x00 0x00 0x00 0x00 0x00 0x00 0x10000 0x3030301 0x1010808 0x3030001 0xa0a0a03 0x2080808 0x2050103 0x2050103 0x50103 0x20202 0x5020500 0x20502 0x00 0x00 0xd000001 0x10028 0x10000 0x03 0x00 0x00 0x00 0x00 0x00 0x00 0x00 0x00 0x10100 0x1000000 0x01 0x303 0x00 0x00 0x00 0x00 0x00 0x00 0x00 0x00 0x00 0x00 0x00 0x00 0x00 0x00 0x00 0x556aa 0xaaaaa 0xaa955 0x55555 0xb3133 0x4cd33 0x4cecc 0xb32cc 0x10300 0x3000100 0x00 0x00 0x00 0x00 0x00 0x00 0x00 0x00 0xffff00 0x1e1e0000 0x800001e 0x1850 0x200 0x200 0x200 0x200 0x1850 0xf320 0x1850050a 0x200 0x200 0x200 0x200 0x1850 0xf320 0x1850050a 0x200 0x200 0x200 0x200 0x1850 0xf320 0x202050a 0x3030202 0x18 0x00 0x00 0x1403 0x00 0x00 0x00 0x30000 0xe0020 0xe0020 0xe0020 0x00 0x00 0x1000000 0x70007 0x50007 0x00 0x00 0x00 0x00 0x00 0x00 0x00 0x00 0x1000101 0x1010101 0x1000101 0x1000100 0x10001 0x10002 0x20100 0x02 0x700 0x00 0x30a0 0x1850 0x30a0 0x1850 0x30a0 0x18501850 0x200 0x200 0x200 0x200 0x1850 0x200 0x200 0x200 0x200 0x1850 0x200 0x200 0x200 0x200 0x10000 0x07 0x81000001 0xf0003f0 0x3fffffff 0xf0000a0 0x377ff000 0xf000020 0x377ff000 0xf000030 0x377ff000 0xf0000b0 0x377ff000 0xf000100 0x377ff000 0xf000110 0x377ff000 0xf000010 0x377ff000 0x3000101 0x42e2e2e 0x6180006 0x61800 0x18 0xc2800a8 0xc2800a8 0xc2800a8 0x500 0x00 0x00 0x00 0x00 0x00 0x00 0x00 0x00 0x4040000 0xd000004 0x128 0x00 0x30003 0x18 0x00 0x00 0x3060002 0x3010301 0x1080801 0x4020201 0x1080804 0x00 0x3030000 0xa0a0a03 0x00 0x00 0x00 0x30300 0x14 0x00 0x1010300 0x00 0x00 0x1000000 0x101 0x55555a5a 0x55555a5a 0x55555a5a 0x55555a5a 0xa0a0001 0x505000a 0x05 0x100 0x30000 0x17030000 0xe0020 0xe0020 0xe0020 0x00 0x00 0x100 0x140a0000 0xa030a 0x3000a03 0x10a000a 0x100 0x1000000 0x00 0x100 0x1e1a0000 0x10010204 0x7070705 0x20000202 0x201000 0x201000 0x4041000 0x10100100 0x10110 0x4b004a 0x1a030000 0x102041e 0x34000000 0x00 0x00 0x00 0x4300 0x1001a 0x4d4d07 0x1a0043 0x4d070001 0x434d 0x1001a 0x4d4d07 0x1a0043 0x4d070001 0x434d 0x1001a 0x4d4d07 0x1a0043 0x4d070001 0x43004d 0x1001a 0x4d4d07 0x1a0043 0x4d070001 0x434d 0x1001a 0x4d4d07 0x1a0043 0x4d070001 0x434d 0x1001a 0x4d4d07 0x1a0043 0x4d070001 0x100004d 0xc800c8 0x60400c8 0xc060f11 0x2200d890 0xa0c2005 0xf11060a 0xc06 0x2200d890 0xa0c2005 0xf11060a 0xc06 0x2200d890 0xa0c2005 0x200020a 0x2000200 0x2000200 0x2000200 0x2000200 0x00 0x00 0x00 0x00 0x00 0x00 0x00 0x00 0x00 0x00 0x00 0x00 0x1000300 0x185000 0xf320 0x1850 0xf320 0x1850 0xf320 0x8000000 0x100 0x00 0x00 0x00 0x00 0x02 0x76543210 0x4c008 0xb3 0x00 0x00 0x10000 0x1665555 0x665555 0x10f00 0x5010200 0x03 0x1700c0 0xcc0101 0x30066 0x00 0x00 0x00 0x00 0x00 0x00 0x00 0x00 0x4080000 0x4080400 0x8000000 0xc00c007 0x100 0x100 0x55555555 0xaaaaaaaa 0x55555555 0xaaaaaaaa 0x5555 0x00 0x00 0x00 0x00 0x00 0x00 0x00 0x00 0x00 0x00 0x00 0x00 0x00 0x00 0x00 0x00 0x00 0x00 0x00 0x200000 0x00 0x00 0x00 0x00 0x00 0x00 0x2700270 0x2700270 0x2700270 0x2700270 0x270 0x00 0x00 0x00 0x00 0x800000 0x800080 0x800080 0x800080 0x800080 0x800080 0x800080 0x800080 0x800080 0xb30080 0x03 0x00 0x20000 0x200 0x00 0x51315152 0xc0013150 0x20000c0 0x100001 0x7054208 0xf0c18 0x1000140 0xc20 0x00 0x00 0x00 0x00 0x00 0x00 0x00 0x00 0x00 0x00 0x00 0x00 0x00 0x00 0x00 0x00 0x00 0x00 0x00 0x00 0x00 0x00 0x00 0x00 0x00 0x00 0x00 0x00 0x00 0x00 0x00 0x00 0x00 0x00 0x00 0x00 0x00 0x76543210 0x4c008 0xb3 0x00 0x00 0x10000 0x1665555 0x665555 0x10f00 0x5010200 0x03 0x1700c0 0xcc0101 0x30066 0x00 0x00 0x00 0x00 0x00 0x00 0x00 0x00 0x4080000 0x4080400 0x8000000 0xc00c007 0x100 0x100 0x55555555 0xaaaaaaaa 0x55555555 0xaaaaaaaa 0x5555 0x00 0x00 0x00 0x00 0x00 0x00 0x00 0x00 0x00 0x00 0x00 0x00 0x00 0x00 0x00 0x00 0x00 0x00 0x00 0x200000 0x00 0x00 0x00 0x00 0x00 0x00 0x2700270 0x2700270 0x2700270 0x2700270 0x270 0x00 0x00 0x00 0x00 0x800000 0x800080 0x800080 0x800080 0x800080 0x800080 0x800080 0x800080 0x800080 0xb30080 0x03 0x00 0x20000 0x200 0x00 0x51315152 0xc0013150 0x20000c0 0x100001 0x7054208 0xf0c18 0x1000140 0xc20 0x00 0x00 0x00 0x00 0x00 0x00 0x00 0x00 0x00 0x00 0x00 0x00 0x00 0x00 0x00 0x00 0x00 0x00 0x00 0x00 0x00 0x00 0x00 0x00 0x00 0x00 0x00 0x00 0x00 0x00 0x00 0x00 0x00 0x00 0x00 0x00 0x00 0x76543210 0x4c008 0xb3 0x00 0x00 0x10000 0x1665555 0x665555 0x10f00 0x5010200 0x03 0x1700c0 0xcc0101 0x30066 0x00 0x00 0x00 0x00 0x00 0x00 0x00 0x00 0x4080000 0x4080400 0x8000000 0xc00c007 0x100 0x100 0x55555555 0xaaaaaaaa 0x55555555 0xaaaaaaaa 0x5555 0x00 0x00 0x00 0x00 0x00 0x00 0x00 0x00 0x00 0x00 0x00 0x00 0x00 0x00 0x00 0x00 0x00 0x00 0x00 0x200000 0x00 0x00 0x00 0x00 0x00 0x00 0x2700270 0x2700270 0x2700270 0x2700270 0x270 0x00 0x00 0x00 0x00 0x800000 0x800080 0x800080 0x800080 0x800080 0x800080 0x800080 0x800080 0x800080 0xb30080 0x03 0x00 0x20000 0x200 0x00 0x51315152 0xc0013150 0x20000c0 0x100001 0x7054208 0xf0c18 0x1000140 0xc20 0x00 0x00 0x00 0x00 0x00 0x00 0x00 0x00 0x00 0x00 0x00 0x00 0x00 0x00 0x00 0x00 0x00 0x00 0x00 0x00 0x00 0x00 0x00 0x00 0x00 0x00 0x00 0x00 0x00 0x00 0x00 0x00 0x00 0x00 0x00 0x00 0x00 0x76543210 0x4c008 0xb3 0x00 0x00 0x10000 0x1665555 0x665555 0x10f00 0x5010200 0x03 0x1700c0 0xcc0101 0x30066 0x00 0x00 0x00 0x00 0x00 0x00 0x00 0x00 0x4080000 0x4080400 0x8000000 0xc00c007 0x100 0x100 0x55555555 0xaaaaaaaa 0x55555555 0xaaaaaaaa 0x5555 0x00 0x00 0x00 0x00 0x00 0x00 0x00 0x00 0x00 0x00 0x00 0x00 0x00 0x00 0x00 0x00 0x00 0x00 0x00 0x200000 0x00 0x00 0x00 0x00 0x00 0x00 0x2700270 0x2700270 0x2700270 0x2700270 0x270 0x00 0x00 0x00 0x00 0x800000 0x800080 0x800080 0x800080 0x800080 0x800080 0x800080 0x800080 0x800080 0xb30080 0x03 0x00 0x20000 0x200 0x00 0x51315152 0xc0013150 0x20000c0 0x100001 0x7054208 0xf0c18 0x1000140 0xc20 0x00 0x00 0x00 0x00 0x00 0x00 0x00 0x00 0x00 0x00 0x00 0x00 0x00 0x00 0x00 0x00 0x00 0x00 0x00 0x00 0x00 0x00 0x00 0x00 0x00 0x00 0x00 0x00 0x00 0x00 0x00 0x00 0x00 0x00 0x00 0x00 0x00 0x00 0x800000 0x00 0x00 0x00 0x00 0x00 0x01 0x00 0x00 0x00 0x400320 0x40 0x806420 0x917531 0x806420 0x1917531 0x20003 0x00 0x00 0x00 0x556aa 0xaaaaa 0xaa955 0x55555 0xb3133 0x4cd33 0x4cecc 0xb32cc 0xa418820 0x103f0000 0x3f 0x38055 0x3800380 0x3800380 0x380 0x42080010 0x03 0x00 0x00 0x00 0x00 0x00 0x00 0x00 0x00 0x00 0x00 0x00 0x00 0x00 0x00 0x00 0x00 0x00 0x00 0x00 0x00 0x00 0x00 0x00 0x00 0x00 0x00 0x00 0x00 0x00 0x00 0x00 0x00 0x00 0x00 0x00 0x00 0x00 0x00 0x00 0x00 0x00 0x00 0x00 0x00 0x00 0x00 0x00 0x00 0x00 0x00 0x00 0x00 0x00 0x00 0x00 0x00 0x00 0x00 0x00 0x00 0x00 0x00 0x00 0x00 0x00 0x00 0x00 0x00 0x00 0x00 0x00 0x00 0x00 0x00 0x00 0x00 0x00 0x00 0x00 0x00 0x00 0x00 0x00 0x00 0x00 0x00 0x00 0x00 0x00 0x00 0x00 0x800000 0x00 0x00 0x00 0x00 0x00 0x01 0x00 0x00 0x00 0x400320 0x40 0x8eca 0x9fdb 0x8eca 0x1009fdb 0x20003 0x00 0x00 0x00 0x556aa 0xaaaaa 0xaa955 0x55555 0xb3133 0x4cd33 0x4cecc 0xb32cc 0x4a0e6 0x80f0000 0x0f 0x38055 0x3800380 0x3800380 0x380 0x42080010 0x03 0x00 0x00 0x00 0x00 0x00 0x00 0x00 0x00 0x00 0x00 0x00 0x00 0x00 0x00 0x00 0x00 0x00 0x00 0x00 0x00 0x00 0x00 0x00 0x00 0x00 0x00 0x00 0x00 0x00 0x00 0x00 0x00 0x00 0x00 0x00 0x00 0x00 0x00 0x00 0x00 0x00 0x00 0x00 0x00 0x00 0x00 0x00 0x00 0x00 0x00 0x00 0x00 0x00 0x00 0x00 0x00 0x00 0x00 0x00 0x00 0x00 0x00 0x00 0x00 0x00 0x00 0x00 0x00 0x00 0x00 0x00 0x00 0x00 0x00 0x00 0x00 0x00 0x00 0x00 0x00 0x00 0x00 0x00 0x00 0x00 0x00 0x00 0x00 0x00 0x00 0x00 0x800000 0x00 0x00 0x00 0x00 0x00 0x01 0x00 0x00 0x00 0x400320 0x40 0x8eca 0x9fdb 0x8eca 0x1009fdb 0x20003 0x00 0x00 0x00 0x556aa 0xaaaaa 0xaa955 0x55555 0xb3133 0x4cd33 0x4cecc 0xb32cc 0x1ee6b16a 0x10000000 0x00 0x38055 0x3800380 0x3800380 0x380 0x42080010 0x03 0x00 0x00 0x00 0x00 0x00 0x00 0x00 0x00 0x00 0x00 0x00 0x00 0x00 0x00 0x00 0x00 0x00 0x00 0x00 0x00 0x00 0x00 0x00 0x00 0x00 0x00 0x00 0x00 0x00 0x00 0x00 0x00 0x00 0x00 0x00 0x00 0x00 0x00 0x00 0x00 0x00 0x00 0x00 0x00 0x00 0x00 0x00 0x00 0x00 0x00 0x00 0x00 0x00 0x00 0x00 0x00 0x00 0x00 0x00 0x00 0x00 0x00 0x00 0x00 0x00 0x00 0x00 0x00 0x00 0x00 0x00 0x00 0x00 0x00 0x00 0x00 0x00 0x00 0x00 0x00 0x00 0x00 0x00 0x00 0x00 0x00 0x00 0x00 0x00 0x00 0x01 0x00 0x1000005 0x4000f00 0x20040 0x20055 0x00 0x00 0x00 0x50 0x00 0x10100 0x601 0x00 0x6400 0x1221102 0x00 0x51f00 0x51f051f 0x51f051f 0x30003 0x3000300 0x300 0x1221102 0x00 0x00 0x3020000 0x01 0x11 0x11 0x400 0x00 0x11 0x11 0x4410 0x4410 0x4410 0x4410 0x4410 0x11 0x4410 0x11 0x4410 0x11 0x4410 0x00 0x00 0x00 0x4000000 0x00 0x00 0x508 0x00 0x00 0x00 0x00 0x00 0x00 0xe4000000 0x00 0x00 0x1010000 0x00>;
		reg = <0x00 0xffa80000 0x00 0x800 0x00 0xffa80800 0x00 0x1800 0x00 0xffa82000 0x00 0x2000 0x00 0xffa84000 0x00 0x1000 0x00 0xffa88000 0x00 0x800 0x00 0xffa88800 0x00 0x1800 0x00 0xffa8a000 0x00 0x2000 0x00 0xffa8c000 0x00 0x1000>;
	};

	serial@ff1a0000 {
		reg-io-width = <0x04>;
		pinctrl-names = "default";
		pinctrl-0 = <0x36>;
		clock-names = "baudclk\0apb_pclk";
		u-boot,dm-pre-reloc;
		interrupts = <0x00 0x64 0x04 0x00>;
		clocks = <0x08 0x53 0x08 0x162>;
		compatible = "rockchip,rk3399-uart\0snps,dw-apb-uart";
		status = "okay";
		reg = <0x00 0xff1a0000 0x00 0x100>;
		reg-shift = <0x02>;
	};

	qos@ffac8000 {
		compatible = "rockchip,rk3399-qos\0syscon";
		reg = <0x00 0xffac8000 0x00 0x20>;
		phandle = <0x67>;
	};

	usb@fe3a0000 {
		phy-names = "usb";
		interrupts = <0x00 0x1c 0x04 0x00>;
		clocks = <0x08 0x1c8 0x08 0x1c9 0x20>;
		compatible = "generic-ohci";
		status = "okay";
		phys = <0x21>;
		reg = <0x00 0xfe3a0000 0x00 0x20000>;
	};

	saradc@ff100000 {
		clock-names = "saradc\0apb_pclk";
		resets = <0x08 0xd4>;
		interrupts = <0x00 0x3e 0x04 0x00>;
		clocks = <0x08 0x50 0x08 0x165>;
		#io-channel-cells = <0x01>;
		compatible = "rockchip,rk3399-saradc";
		status = "disabled";
		reg = <0x00 0xff100000 0x00 0x100>;
		reset-names = "saradc-apb";
	};

	qos@ffad8080 {
		compatible = "rockchip,rk3399-qos\0syscon";
		reg = <0x00 0xffad8080 0x00 0x20>;
	};

	usb@fe3e0000 {
		phy-names = "usb";
		interrupts = <0x00 0x20 0x04 0x00>;
		clocks = <0x08 0x1ca 0x08 0x1cb 0x22>;
		compatible = "generic-ohci";
		status = "okay";
		phys = <0x23>;
		reg = <0x00 0xfe3e0000 0x00 0x20000>;
	};

	i2c@ff120000 {
		pinctrl-names = "default";
		#address-cells = <0x01>;
		pinctrl-0 = <0x2f>;
		clock-names = "i2c\0pclk";
		assigned-clocks = <0x08 0x42>;
		assigned-clock-rates = <0xbebc200>;
		interrupts = <0x00 0x23 0x04 0x00>;
		clocks = <0x08 0x42 0x08 0x156>;
		#size-cells = <0x00>;
		compatible = "rockchip,rk3399-i2c";
		status = "disabled";
		reg = <0x00 0xff120000 0x00 0x1000>;
	};

	qos@ffa58000 {
		compatible = "rockchip,rk3399-qos\0syscon";
		reg = <0x00 0xffa58000 0x00 0x20>;
		phandle = <0x5c>;
	};

	mmc@fe320000 {
		power-domains = <0x16 0x1b>;
		fifo-depth = <0x100>;
		u-boot,spl-fifo-mode;
		pinctrl-names = "default";
		pinctrl-0 = <0x1c 0x1d 0x1e>;
		clock-names = "biu\0ciu\0ciu-drive\0ciu-sample";
		cap-sd-highspeed;
		assigned-clocks = <0x08 0x1cd>;
		bus-width = <0x04>;
		u-boot,dm-pre-reloc;
		assigned-clock-rates = <0xbebc200>;
		resets = <0x08 0x7a>;
		interrupts = <0x00 0x41 0x04 0x00>;
		clocks = <0x08 0x1ce 0x08 0x4c 0x08 0x9a 0x08 0x9b>;
		compatible = "rockchip,rk3399-dw-mshc\0rockchip,rk3288-dw-mshc";
		status = "okay";
		disable-wp;
		reg = <0x00 0xfe320000 0x00 0x4000>;
		max-frequency = <0x8f0d180>;
		cap-mmc-highspeed;
		reset-names = "reset";
		cd-gpios = <0x1b 0x07 0x01>;
	};

	hdmi-sound {
		simple-audio-card,name = "hdmi-sound";
		simple-audio-card,format = "i2s";
		compatible = "simple-audio-card";
		status = "disabled";
		simple-audio-card,mclk-fs = <0x100>;

		simple-audio-card,cpu {
			sound-dai = <0x95>;
		};

		simple-audio-card,codec {
			sound-dai = <0x96>;
		};
	};

	syscon@ff770000 {
		#address-cells = <0x01>;
		u-boot,dm-pre-reloc;
		#size-cells = <0x01>;
		compatible = "rockchip,rk3399-grf\0syscon\0simple-mfd";
		reg = <0x00 0xff770000 0x00 0x10000>;
		phandle = <0x17>;

		mipi-dphy-rx0 {
			power-domains = <0x16 0x0f>;
			clock-names = "dphy-ref\0dphy-cfg\0grf";
			clocks = <0x08 0x77 0x08 0xa5 0x08 0x16f>;
			#phy-cells = <0x00>;
			compatible = "rockchip,rk3399-mipi-dphy-rx0";
			status = "disabled";
			phandle = <0x94>;
		};

		pcie-phy {
			clock-names = "refclk";
			resets = <0x08 0x87>;
			clocks = <0x08 0x8a>;
			drive-impedance-ohm = <0x32>;
			#phy-cells = <0x01>;
			compatible = "rockchip,rk3399-pcie-phy";
			status = "disabled";
			phandle = <0x13>;
			reset-names = "phy";
		};

		usb2phy@e460 {
			clock-output-names = "clk_usbphy1_480m";
			clock-names = "phyclk";
			clocks = <0x08 0x7c>;
			#clock-cells = <0x00>;
			compatible = "rockchip,rk3399-usb2phy";
			status = "okay";
			reg = <0xe460 0x10>;
			phandle = <0x22>;

			host-port {
				phy-supply = <0x82>;
				interrupts = <0x00 0x1f 0x04 0x00>;
				#phy-cells = <0x00>;
				status = "okay";
				interrupt-names = "linestate";
				phandle = <0x23>;
			};

			otg-port {
				interrupts = <0x00 0x6c 0x04 0x00 0x00 0x6d 0x04 0x00 0x00 0x6f 0x04 0x00>;
				#phy-cells = <0x00>;
				status = "okay";
				interrupt-names = "otg-bvalid\0otg-id\0linestate";
				phandle = <0x28>;
			};
		};

		usb2phy@e450 {
			clock-output-names = "clk_usbphy0_480m";
			clock-names = "phyclk";
			clocks = <0x08 0x7b>;
			extcon = <0x24>;
			#clock-cells = <0x00>;
			compatible = "rockchip,rk3399-usb2phy";
			status = "okay";
			reg = <0xe450 0x10>;
			phandle = <0x20>;

			host-port {
				phy-supply = <0x82>;
				interrupts = <0x00 0x1b 0x04 0x00>;
				#phy-cells = <0x00>;
				status = "okay";
				interrupt-names = "linestate";
				phandle = <0x21>;
			};

			otg-port {
				interrupts = <0x00 0x67 0x04 0x00 0x00 0x68 0x04 0x00 0x00 0x6a 0x04 0x00>;
				#phy-cells = <0x00>;
				status = "okay";
				interrupt-names = "otg-bvalid\0otg-id\0linestate";
				phandle = <0x25>;
			};
		};

		io-domains {
			compatible = "rockchip,rk3399-io-voltage-domain";
			status = "disabled";
		};

		phy@f780 {
			clock-names = "emmcclk";
			u-boot,dm-pre-reloc;
			clocks = <0x83>;
			#phy-cells = <0x00>;
			compatible = "rockchip,rk3399-emmc-phy";
			status = "okay";
			reg = <0xf780 0x24>;
			phandle = <0x1f>;
		};
	};

	efuse@ff690000 {
		#address-cells = <0x01>;
		clock-names = "pclk_efuse";
		clocks = <0x08 0x17d>;
		#size-cells = <0x01>;
		compatible = "rockchip,rk3399-efuse";
		reg = <0x00 0xff690000 0x00 0x80>;

		cpu-leakage@1a {
			reg = <0x1a 0x01>;
		};

		center-leakage@19 {
			reg = <0x19 0x01>;
		};

		logic-leakage@1b {
			reg = <0x1b 0x01>;
		};

		cpu-id@7 {
			reg = <0x07 0x10>;
		};

		gpu-leakage@18 {
			reg = <0x18 0x01>;
		};

		wafer-info@1c {
			reg = <0x1c 0x01>;
		};

		cpu-leakage@17 {
			reg = <0x17 0x01>;
		};
	};

	qos@ffa70080 {
		compatible = "rockchip,rk3399-qos\0syscon";
		reg = <0x00 0xffa70080 0x00 0x20>;
		phandle = <0x61>;
	};

	interrupt-controller@fee00000 {
		#address-cells = <0x02>;
		interrupts = <0x01 0x09 0x04 0x00>;
		#size-cells = <0x02>;
		compatible = "arm,gic-v3";
		ranges;
		#interrupt-cells = <0x04>;
		reg = <0x00 0xfee00000 0x00 0x10000 0x00 0xfef00000 0x00 0xc0000 0x00 0xfff00000 0x00 0x10000 0x00 0xfff10000 0x00 0x10000 0x00 0xfff20000 0x00 0x10000>;
		phandle = <0x01>;
		interrupt-controller;

		interrupt-controller@fee20000 {
			msi-controller;
			compatible = "arm,gic-v3-its";
			reg = <0x00 0xfee20000 0x00 0x20000>;
			phandle = <0x12>;
			#msi-cells = <0x01>;
		};

		ppi-partitions {

			interrupt-partition-0 {
				affinity = <0x02 0x03 0x04 0x05>;
				phandle = <0x0f>;
			};

			interrupt-partition-1 {
				affinity = <0x06 0x07>;
				phandle = <0x10>;
			};
		};
	};

	i2c@ff160000 {
		pinctrl-names = "default";
		#address-cells = <0x01>;
		pinctrl-0 = <0x33>;
		clock-names = "i2c\0pclk";
		assigned-clocks = <0x08 0x46>;
		assigned-clock-rates = <0xbebc200>;
		interrupts = <0x00 0x24 0x04 0x00>;
		clocks = <0x08 0x46 0x08 0x15a>;
		#size-cells = <0x00>;
		compatible = "rockchip,rk3399-i2c";
		status = "disabled";
		reg = <0x00 0xff160000 0x00 0x1000>;
	};

	qos@ffa98000 {
		compatible = "rockchip,rk3399-qos\0syscon";
		reg = <0x00 0xffa98000 0x00 0x20>;
		phandle = <0x55>;
	};

	display-subsystem {
		ports = <0x0d 0x0e>;
		compatible = "rockchip,display-subsystem";
	};

	backlight {
		default-brightness-level = <0xc8>;
		compatible = "pwm-backlight";
		brightness-levels = <0x00 0x01 0x02 0x03 0x04 0x05 0x06 0x07 0x08 0x09 0x0a 0x0b 0x0c 0x0d 0x0e 0x0f 0x10 0x11 0x12 0x13 0x14 0x15 0x16 0x17 0x18 0x19 0x1a 0x1b 0x1c 0x1d 0x1e 0x1f 0x20 0x21 0x22 0x23 0x24 0x25 0x26 0x27 0x28 0x29 0x2a 0x2b 0x2c 0x2d 0x2e 0x2f 0x30 0x31 0x32 0x33 0x34 0x35 0x36 0x37 0x38 0x39 0x3a 0x3b 0x3c 0x3d 0x3e 0x3f 0x40 0x41 0x42 0x43 0x44 0x45 0x46 0x47 0x48 0x49 0x4a 0x4b 0x4c 0x4d 0x4e 0x4f 0x50 0x51 0x52 0x53 0x54 0x55 0x56 0x57 0x58 0x59 0x5a 0x5b 0x5c 0x5d 0x5e 0x5f 0x60 0x61 0x62 0x63 0x64 0x65 0x66 0x67 0x68 0x69 0x6a 0x6b 0x6c 0x6d 0x6e 0x6f 0x70 0x71 0x72 0x73 0x74 0x75 0x76 0x77 0x78 0x79 0x7a 0x7b 0x7c 0x7d 0x7e 0x7f 0x80 0x81 0x82 0x83 0x84 0x85 0x86 0x87 0x88 0x89 0x8a 0x8b 0x8c 0x8d 0x8e 0x8f 0x90 0x91 0x92 0x93 0x94 0x95 0x96 0x97 0x98 0x99 0x9a 0x9b 0x9c 0x9d 0x9e 0x9f 0xa0 0xa1 0xa2 0xa3 0xa4 0xa5 0xa6 0xa7 0xa8 0xa9 0xaa 0xab 0xac 0xad 0xae 0xaf 0xb0 0xb1 0xb2 0xb3 0xb4 0xb5 0xb6 0xb7 0xb8 0xb9 0xba 0xbb 0xbc 0xbd 0xbe 0xbf 0xc0 0xc1 0xc2 0xc3 0xc4 0xc5 0xc6 0xc7 0xc8 0xc9 0xca 0xcb 0xcc 0xcd 0xce 0xcf 0xd0 0xd1 0xd2 0xd3 0xd4 0xd5 0xd6 0xd7 0xd8 0xd9 0xda 0xdb 0xdc 0xdd 0xde 0xdf 0xe0 0xe1 0xe2 0xe3 0xe4 0xe5 0xe6 0xe7 0xe8 0xe9 0xea 0xeb 0xec 0xed 0xee 0xef 0xf0 0xf1 0xf2 0xf3 0xf4 0xf5 0xf6 0xf7 0xf8 0xf9 0xfa 0xfb 0xfc 0xfd 0xfe 0xff>;
		phandle = <0xaa>;
		pwms = <0xa9 0x00 0x61a8 0x00>;
	};

	dp@fec00000 {
		power-domains = <0x16 0x15>;
		clock-names = "core-clk\0pclk\0spdif\0grf";
		assigned-clocks = <0x08 0x72 0x08 0xa1>;
		assigned-clock-rates = <0x5f5e100 0xbebc200>;
		resets = <0x08 0x103 0x08 0x148 0x08 0x14a 0x08 0xfd>;
		interrupts = <0x00 0x09 0x04 0x00>;
		clocks = <0x08 0x72 0x08 0x175 0x08 0xa1 0x08 0x16f>;
		#sound-dai-cells = <0x01>;
		compatible = "rockchip,rk3399-cdn-dp";
		status = "disabled";
		rockchip,grf = <0x17>;
		phys = <0x2a 0x2b>;
		reg = <0x00 0xfec00000 0x00 0x100000>;
		reset-names = "spdif\0dptx\0apb\0core";

		ports {

			port {
				#address-cells = <0x01>;
				#size-cells = <0x00>;

				endpoint@1 {
					remote-endpoint = <0x2d>;
					reg = <0x01>;
					phandle = <0x8c>;
				};

				endpoint@0 {
					remote-endpoint = <0x2c>;
					reg = <0x00>;
					phandle = <0x92>;
				};
			};
		};
	};

	rng@ff8b8000 {
		compatible = "rockchip,cryptov1-rng";
		status = "okay";
		reg = <0x00 0xff8b8000 0x00 0x1000>;
	};

	iommu@ff670800 {
		clock-names = "aclk\0iface";
		interrupts = <0x00 0x2a 0x04 0x00>;
		clocks = <0x08 0xe1 0x08 0x1dd>;
		#iommu-cells = <0x00>;
		compatible = "rockchip,iommu";
		status = "disabled";
		interrupt-names = "iep_mmu";
		reg = <0x00 0xff670800 0x00 0x40>;
	};

	spi@ff1e0000 {
		pinctrl-names = "default";
		#address-cells = <0x01>;
		pinctrl-0 = <0x41 0x42 0x43 0x44>;
		clock-names = "spiclk\0apb_pclk";
		interrupts = <0x00 0x34 0x04 0x00>;
		clocks = <0x08 0x49 0x08 0x15d>;
		#size-cells = <0x00>;
		dma-names = "tx\0rx";
		compatible = "rockchip,rk3399-spi\0rockchip,rk3066-spi";
		status = "disabled";
		reg = <0x00 0xff1e0000 0x00 0x1000>;
		dmas = <0x38 0x0e 0x38 0x0f>;
	};

	rga@ff680000 {
		power-domains = <0x16 0x21>;
		clock-names = "aclk\0hclk\0sclk";
		resets = <0x08 0x6a 0x08 0x67 0x08 0x69>;
		interrupts = <0x00 0x37 0x04 0x00>;
		clocks = <0x08 0xdc 0x08 0x1e5 0x08 0x6d>;
		compatible = "rockchip,rk3399-rga";
		reg = <0x00 0xff680000 0x00 0x10000>;
		reset-names = "core\0axi\0ahb";
	};

	i2s@ff890000 {
		power-domains = <0x16 0x1c>;
		pinctrl-names = "default";
		pinctrl-0 = <0x86>;
		clock-names = "i2s_clk\0i2s_hclk";
		interrupts = <0x00 0x28 0x04 0x00>;
		clocks = <0x08 0x57 0x08 0x1d5>;
		dma-names = "tx\0rx";
		#sound-dai-cells = <0x00>;
		compatible = "rockchip,rk3399-i2s\0rockchip,rk3066-i2s";
		status = "disabled";
		reg = <0x00 0xff890000 0x00 0x1000>;
		dmas = <0x49 0x02 0x49 0x03>;
	};

	thermal-zones {

		cpu-thermal {
			polling-delay = <0x3e8>;
			polling-delay-passive = <0x64>;
			thermal-sensors = <0x4e 0x00>;

			trips {

				cpu_crit {
					temperature = <0x17318>;
					hysteresis = <0x7d0>;
					type = "critical";
				};

				cpu_alert0 {
					temperature = <0x11170>;
					hysteresis = <0x7d0>;
					type = "passive";
					phandle = <0x4f>;
				};

				cpu_alert1 {
					temperature = <0x124f8>;
					hysteresis = <0x7d0>;
					type = "passive";
					phandle = <0x50>;
				};
			};

			cooling-maps {

				map0 {
					trip = <0x4f>;
					cooling-device = <0x06 0xffffffff 0xffffffff 0x07 0xffffffff 0xffffffff>;
				};

				map1 {
					trip = <0x50>;
					cooling-device = <0x02 0xffffffff 0xffffffff 0x03 0xffffffff 0xffffffff 0x04 0xffffffff 0xffffffff 0x05 0xffffffff 0xffffffff 0x06 0xffffffff 0xffffffff 0x07 0xffffffff 0xffffffff>;
				};
			};
		};

		gpu-thermal {
			polling-delay = <0x3e8>;
			polling-delay-passive = <0x64>;
			thermal-sensors = <0x4e 0x01>;

			trips {

				gpu_alert0 {
					temperature = <0x124f8>;
					hysteresis = <0x7d0>;
					type = "passive";
					phandle = <0x51>;
				};

				gpu_crit {
					temperature = <0x17318>;
					hysteresis = <0x7d0>;
					type = "critical";
				};
			};

			cooling-maps {

				map0 {
					trip = <0x51>;
					cooling-device = <0x52 0xffffffff 0xffffffff>;
				};
			};
		};
	};

	video-codec@ff650000 {
		power-domains = <0x16 0x1f>;
		iommus = <0x7f>;
		clock-names = "aclk\0hclk";
		interrupts = <0x00 0x72 0x04 0x00 0x00 0x71 0x04 0x00>;
		clocks = <0x08 0xeb 0x08 0x1ea>;
		compatible = "rockchip,rk3399-vpu";
		interrupt-names = "vepu\0vdpu";
		reg = <0x00 0xff650000 0x00 0x800>;
	};

	pmu_a72 {
		interrupts = <0x01 0x07 0x08 0x10>;
		compatible = "arm,cortex-a72-pmu";
	};

	vcc5v0-sys {
		regulator-max-microvolt = <0x4c4b40>;
		regulator-boot-on;
		regulator-always-on;
		regulator-min-microvolt = <0x4c4b40>;
		regulator-name = "vcc5v0_sys";
		compatible = "regulator-fixed";
		phandle = <0x73>;
	};

	iommu@ff914000 {
		power-domains = <0x16 0x13>;
		clock-names = "aclk\0iface";
		interrupts = <0x00 0x2b 0x04 0x00>;
		clocks = <0x08 0xe9 0x08 0x1e3>;
		#iommu-cells = <0x00>;
		compatible = "rockchip,iommu";
		rockchip,disable-mmu-reset;
		interrupt-names = "isp0_mmu";
		reg = <0x00 0xff914000 0x00 0x100 0x00 0xff915000 0x00 0x100>;
		phandle = <0x93>;
	};

	qos@ffaa0000 {
		compatible = "rockchip,rk3399-qos\0syscon";
		reg = <0x00 0xffaa0000 0x00 0x20>;
		phandle = <0x63>;
	};

	edp-panel {
		power-supply = <0xab>;
		backlight = <0xaa>;
		compatible = "lg,lp079qx1-sp0v";
		enable-gpios = <0x71 0x0d 0x00>;

		port {

			endpoint {
				remote-endpoint = <0xac>;
				phandle = <0xa0>;
			};
		};
	};

	psci {
		method = "smc";
		compatible = "arm,psci-1.0";
	};

	xin24m {
		clock-output-names = "xin24m";
		#clock-cells = <0x00>;
		clock-frequency = <0x16e3600>;
		compatible = "fixed-clock";
	};

	spi@ff200000 {
		power-domains = <0x16 0x1c>;
		pinctrl-names = "default";
		#address-cells = <0x01>;
		pinctrl-0 = <0x4a 0x4b 0x4c 0x4d>;
		clock-names = "spiclk\0apb_pclk";
		interrupts = <0x00 0x84 0x04 0x00>;
		clocks = <0x08 0x4b 0x08 0x15f>;
		#size-cells = <0x00>;
		dma-names = "tx\0rx";
		compatible = "rockchip,rk3399-spi\0rockchip,rk3066-spi";
		status = "disabled";
		reg = <0x00 0xff200000 0x00 0x1000>;
		dmas = <0x49 0x08 0x49 0x09>;
	};

	qos@ffae0000 {
		compatible = "rockchip,rk3399-qos\0syscon";
		reg = <0x00 0xffae0000 0x00 0x20>;
		phandle = <0x5b>;
	};

	qos@ffab0080 {
		compatible = "rockchip,rk3399-qos\0syscon";
		reg = <0x00 0xffab0080 0x00 0x20>;
		phandle = <0x57>;
	};

	iommu@ff903f00 {
		power-domains = <0x16 0x11>;
		clock-names = "aclk\0iface";
		interrupts = <0x00 0x76 0x04 0x00>;
		clocks = <0x08 0xd9 0x08 0x1d9>;
		#iommu-cells = <0x00>;
		compatible = "rockchip,iommu";
		status = "disabled";
		interrupt-names = "vopb_mmu";
		reg = <0x00 0xff903f00 0x00 0x100>;
		phandle = <0x8d>;
	};

	fit-images {

		uboot {
			load = <0x00 0x200000>;
			os = "U-Boot";
			type = "standalone";
			size = <0xe1f48>;
			arch = "arm64";
		};

		atf_3 {
			load = <0x00 0xff8c0000>;
			os = "arm-trusted-firmware";
			type = "firmware";
			size = <0x2000>;
			arch = "arm64";
		};

		atf_2 {
			load = <0x00 0xff3b0000>;
			os = "arm-trusted-firmware";
			type = "firmware";
			size = <0x1f58>;
			arch = "arm64";
		};
	};

	qos@ffa76000 {
		compatible = "rockchip,rk3399-qos\0syscon";
		reg = <0x00 0xffa76000 0x00 0x20>;
		phandle = <0x5f>;
	};

	serial@ff1b0000 {
		reg-io-width = <0x04>;
		pinctrl-names = "default";
		pinctrl-0 = <0x37>;
		clock-names = "baudclk\0apb_pclk";
		interrupts = <0x00 0x65 0x04 0x00>;
		clocks = <0x08 0x54 0x08 0x163>;
		compatible = "rockchip,rk3399-uart\0snps,dw-apb-uart";
		status = "disabled";
		reg = <0x00 0xff1b0000 0x00 0x100>;
		reg-shift = <0x02>;
	};

	watchdog@ff848000 {
		interrupts = <0x00 0x78 0x04 0x00>;
		clocks = <0x08 0x17c>;
		compatible = "rockchip,rk3399-wdt\0snps,dw-wdt";
		reg = <0x00 0xff848000 0x00 0x100>;
	};

	qos@ffaa8080 {
		compatible = "rockchip,rk3399-qos\0syscon";
		reg = <0x00 0xffaa8080 0x00 0x20>;
		phandle = <0x66>;
	};

	qos@ffa70000 {
		compatible = "rockchip,rk3399-qos\0syscon";
		reg = <0x00 0xffa70000 0x00 0x20>;
		phandle = <0x60>;
	};

	i2c@ff130000 {
		pinctrl-names = "default";
		#address-cells = <0x01>;
		pinctrl-0 = <0x30>;
		clock-names = "i2c\0pclk";
		assigned-clocks = <0x08 0x43>;
		assigned-clock-rates = <0xbebc200>;
		interrupts = <0x00 0x22 0x04 0x00>;
		clocks = <0x08 0x43 0x08 0x157>;
		#size-cells = <0x00>;
		compatible = "rockchip,rk3399-i2c";
		status = "disabled";
		reg = <0x00 0xff130000 0x00 0x1000>;
	};

	mmc@fe330000 {
		power-domains = <0x16 0x17>;
		mmc-hs400-enhanced-strobe;
		disable-cqe-dcmd;
		clock-output-names = "emmc_cardclock";
		phy-names = "phy_arasan";
		clock-names = "clk_xin\0clk_ahb";
		assigned-clocks = <0x08 0x4e>;
		bus-width = <0x08>;
		non-removable;
		u-boot,dm-pre-reloc;
		assigned-clock-rates = <0xbebc200>;
		mmc-hs400-1_8v;
		interrupts = <0x00 0x0b 0x04 0x00>;
		clocks = <0x08 0x4e 0x08 0xf0>;
		arasan,soc-ctl-syscon = <0x17>;
		#clock-cells = <0x00>;
		compatible = "rockchip,rk3399-sdhci-5.1\0arasan,sdhci-5.1";
		status = "okay";
		phys = <0x1f>;
		reg = <0x00 0xfe330000 0x00 0x10000>;
		phandle = <0x83>;
		max-frequency = <0xbebc200>;
	};

	vdd-center {
		regulator-max-microvolt = <0x155cc0>;
		regulator-boot-on;
		regulator-init-microvolt = <0xdbba0>;
		regulator-always-on;
		regulator-min-microvolt = "\0\f5";
		regulator-name = "vdd_center";
		compatible = "pwm-regulator";
		status = "okay";
		pwms = <0xad 0x00 0x61a8 0x00>;
	};

	tsadc@ff260000 {
		pinctrl-names = "init\0default\0sleep";
		pinctrl-2 = <0x53>;
		pinctrl-0 = <0x53>;
		clock-names = "tsadc\0apb_pclk";
		assigned-clocks = <0x08 0x4f>;
		assigned-clock-rates = <0xb71b0>;
		resets = <0x08 0xe8>;
		interrupts = <0x00 0x61 0x04 0x00>;
		clocks = <0x08 0x4f 0x08 0x164>;
		#thermal-sensor-cells = <0x01>;
		compatible = "rockchip,rk3399-tsadc";
		pinctrl-1 = <0x54>;
		status = "disabled";
		rockchip,grf = <0x17>;
		reg = <0x00 0xff260000 0x00 0x100>;
		phandle = <0x4e>;
		reset-names = "tsadc-apb";
		rockchip,hw-tshut-temp = <0x17318>;
	};

	usb@fe900000 {
		pinctrl-names = "default";
		#address-cells = <0x02>;
		pinctrl-0 = <0x27>;
		clock-names = "ref_clk\0suspend_clk\0bus_clk\0aclk_usb3_rksoc_axi_perf\0aclk_usb3\0grf_clk";
		resets = <0x08 0x126>;
		clocks = <0x08 0x82 0x08 0x84 0x08 0xf7 0x08 0xf8 0x08 0xf4 0x08 0xf9>;
		#size-cells = <0x02>;
		compatible = "rockchip,rk3399-dwc3";
		ranges;
		status = "okay";
		reset-names = "usb3-otg";

		usb@fe900000 {
			power-domains = <0x16 0x18>;
			snps,dis_enblslpm_quirk;
			phy-names = "usb2-phy\0usb3-phy";
			clock-names = "ref\0bus_early\0suspend";
			snps,dis-u2-freeclk-exists-quirk;
			phy_type = "utmi_wide";
			snps,dis_u2_susphy_quirk;
			interrupts = <0x00 0x6e 0x04 0x00>;
			clocks = <0x08 0x82 0x08 0xf7 0x08 0x84>;
			compatible = "snps,dwc3";
			snps,dis-del-phy-power-chg-quirk;
			status = "okay";
			phys = <0x28 0x29>;
			reg = <0x00 0xfe900000 0x00 0x100000>;
			dr_mode = "host";
			snps,dis-tx-ipgap-linecheck-quirk;
		};
	};

	serial@ff180000 {
		reg-io-width = <0x04>;
		pinctrl-names = "default";
		pinctrl-0 = <0x34>;
		clock-names = "baudclk\0apb_pclk";
		u-boot,dm-pre-reloc;
		interrupts = <0x00 0x63 0x04 0x00>;
		clocks = <0x08 0x51 0x08 0x160>;
		compatible = "rockchip,rk3399-uart\0snps,dw-apb-uart";
		status = "disabled";
		reg = <0x00 0xff180000 0x00 0x100>;
		reg-shift = <0x02>;
	};

	usb@fe380000 {
		phy-names = "usb";
		interrupts = <0x00 0x1a 0x04 0x00>;
		clocks = <0x08 0x1c8 0x08 0x1c9 0x20>;
		compatible = "generic-ehci";
		status = "okay";
		phys = <0x21>;
		reg = <0x00 0xfe380000 0x00 0x20000>;
	};

	ethernet@fe300000 {
		power-domains = <0x16 0x16>;
		pinctrl-names = "default";
		phy-supply = <0x19>;
		phy-mode = "rgmii";
		snps,txpbl = <0x04>;
		snps,reset-active-low;
		pinctrl-0 = <0x1a>;
		clock-names = "stmmaceth\0mac_clk_rx\0mac_clk_tx\0clk_mac_ref\0clk_mac_refout\0aclk_mac\0pclk_mac";
		assigned-clocks = <0x08 0xa6>;
		assigned-clock-parents = <0x18>;
		local-mac-address = [82 c8 9f 3d 3c fd];
		resets = <0x08 0x89>;
		interrupts = <0x00 0x0c 0x04 0x00>;
		clocks = <0x08 0x69 0x08 0x67 0x08 0x68 0x08 0x66 0x08 0x6a 0x08 0xd5 0x08 0x166>;
		clock_in_out = "input";
		compatible = "rockchip,rk3399-gmac";
		status = "okay";
		rockchip,grf = <0x17>;
		interrupt-names = "macirq";
		snps,reset-gpio = <0x14 0x0f 0x01>;
		reg = <0x00 0xfe300000 0x00 0x10000>;
		rx_delay = <0x11>;
		reset-names = "stmmaceth";
		tx_delay = <0x28>;
		snps,reset-delays-us = <0x00 0x2710 0xc350>;
	};

	spi@ff350000 {
		pinctrl-names = "default";
		#address-cells = <0x01>;
		pinctrl-0 = <0x6b 0x6c 0x6d 0x6e>;
		clock-names = "spiclk\0apb_pclk";
		interrupts = <0x00 0x3c 0x04 0x00>;
		clocks = <0x6a 0x03 0x6a 0x1f>;
		#size-cells = <0x00>;
		compatible = "rockchip,rk3399-spi\0rockchip,rk3066-spi";
		status = "disabled";
		reg = <0x00 0xff350000 0x00 0x1000>;
	};

	vcc-phy-regulator {
		regulator-boot-on;
		regulator-always-on;
		regulator-name = "vcc_phy";
		compatible = "regulator-fixed";
		phandle = <0x19>;
	};

	spi@ff1f0000 {
		pinctrl-names = "default";
		#address-cells = <0x01>;
		pinctrl-0 = <0x45 0x46 0x47 0x48>;
		clock-names = "spiclk\0apb_pclk";
		interrupts = <0x00 0x43 0x04 0x00>;
		clocks = <0x08 0x4a 0x08 0x15e>;
		#size-cells = <0x00>;
		dma-names = "tx\0rx";
		compatible = "rockchip,rk3399-spi\0rockchip,rk3066-spi";
		status = "disabled";
		reg = <0x00 0xff1f0000 0x00 0x1000>;
		dmas = <0x38 0x12 0x38 0x13>;
	};

	syscon@ff320000 {
		u-boot,dm-pre-reloc;
		compatible = "rockchip,rk3399-pmugrf\0syscon\0simple-mfd";
		reg = <0x00 0xff320000 0x00 0x1000>;
		phandle = <0x81>;

		io-domains {
			compatible = "rockchip,rk3399-pmu-io-voltage-domain";
			status = "disabled";
		};
	};

	mipi@ff960000 {
		power-domains = <0x16 0x0f>;
		#address-cells = <0x01>;
		clock-names = "ref\0pclk\0phy_cfg\0grf";
		resets = <0x08 0xfb>;
		interrupts = <0x00 0x2d 0x04 0x00>;
		clocks = <0x08 0xa2 0x08 0x170 0x08 0xa3 0x08 0x16f>;
		#size-cells = <0x00>;
		compatible = "rockchip,rk3399-mipi-dsi\0snps,dw-mipi-dsi";
		status = "disabled";
		rockchip,grf = <0x17>;
		reg = <0x00 0xff960000 0x00 0x8000>;
		reset-names = "apb";

		ports {
			#address-cells = <0x01>;
			#size-cells = <0x00>;

			port@0 {
				#address-cells = <0x01>;
				#size-cells = <0x00>;
				reg = <0x00>;

				endpoint@1 {
					remote-endpoint = <0x9a>;
					reg = <0x01>;
					phandle = <0x88>;
				};

				endpoint@0 {
					remote-endpoint = <0x99>;
					reg = <0x00>;
					phandle = <0x8f>;
				};
			};
		};
	};

	iommu@ff8f3f00 {
		power-domains = <0x16 0x12>;
		clock-names = "aclk\0iface";
		interrupts = <0x00 0x77 0x04 0x00>;
		clocks = <0x08 0xdb 0x08 0x1db>;
		#iommu-cells = <0x00>;
		compatible = "rockchip,iommu";
		status = "disabled";
		interrupt-names = "vopl_mmu";
		reg = <0x00 0xff8f3f00 0x00 0x100>;
		phandle = <0x87>;
	};

	timer {
		arm,no-tick-in-suspend;
		interrupts = <0x01 0x0d 0x08 0x00 0x01 0x0e 0x08 0x00 0x01 0x0b 0x08 0x00 0x01 0x0a 0x08 0x00>;
		compatible = "arm,armv8-timer";
	};

	video-codec@ff660000 {
		power-domains = <0x16 0x20>;
		iommus = <0x80>;
		clock-names = "axi\0ahb\0cabac\0core";
		interrupts = <0x00 0x74 0x04 0x00>;
		clocks = <0x08 0xed 0x08 0x1ec 0x08 0x9f 0x08 0x9e>;
		compatible = "rockchip,rk3399-vdec";
		reg = <0x00 0xff660000 0x00 0x400>;
	};

	iommu@ff924000 {
		power-domains = <0x16 0x14>;
		clock-names = "aclk\0iface";
		interrupts = <0x00 0x2c 0x04 0x00>;
		clocks = <0x08 0xea 0x08 0x1e4>;
		#iommu-cells = <0x00>;
		compatible = "rockchip,iommu";
		rockchip,disable-mmu-reset;
		interrupt-names = "isp1_mmu";
		reg = <0x00 0xff924000 0x00 0x100 0x00 0xff925000 0x00 0x100>;
	};

	i2c@ff3c0000 {
		pinctrl-names = "default";
		#address-cells = <0x01>;
		pinctrl-0 = <0x70>;
		clock-names = "i2c\0pclk";
		assigned-clocks = <0x6a 0x09>;
		u-boot,dm-pre-reloc;
		assigned-clock-rates = <0xbebc200>;
		interrupts = <0x00 0x39 0x04 0x00>;
		clocks = <0x6a 0x09 0x6a 0x1b>;
		#size-cells = <0x00>;
		compatible = "rockchip,rk3399-i2c";
		status = "okay";
		reg = <0x00 0xff3c0000 0x00 0x1000>;

		pmic@20 {
			pinctrl-names = "default";
			rockchip,system-power-controller;
			clock-output-names = "rk808-clkout1\0rk808-clkout2";
			pinctrl-0 = <0x72>;
			u-boot,dm-pre-reloc;
			wakeup-source;
			interrupts = <0x15 0x08>;
			#clock-cells = <0x01>;
			interrupt-parent = <0x71>;
			vcc1-supply = <0x73>;
			vcc2-supply = <0x73>;
			compatible = "rockchip,rk809";
			vcc3-supply = <0x73>;
			vcc4-supply = <0x73>;
			vcc5-supply = <0x74>;
			reg = <0x20>;
			vcc6-supply = <0x74>;
			vcc7-supply = <0x75>;
			vcc8-supply = <0x75>;
			vcc9-supply = <0x73>;

			regulators {

				DCDC_REG4 {
					regulator-max-microvolt = <0x325aa0>;
					regulator-boot-on;
					regulator-always-on;
					regulator-min-microvolt = <0x325aa0>;
					regulator-name = "vcc3v3_sys";
					regulator-initial-mode = <0x02>;
					phandle = <0x75>;

					regulator-state-mem {
						regulator-suspend-microvolt = <0x325aa0>;
						regulator-on-in-suspend;
					};
				};

				LDO_REG4 {
					regulator-max-microvolt = <0x1b7740>;
					regulator-boot-on;
					regulator-always-on;
					regulator-min-microvolt = <0x1b7740>;
					regulator-name = "vcca_1v8";

					regulator-state-mem {
						regulator-on-in-suspend;
					};
				};

				DCDC_REG2 {
					regulator-max-microvolt = <0x149970>;
					regulator-boot-on;
					regulator-always-on;
					regulator-min-microvolt = <0xb71b0>;
					regulator-name = "vdd_cpu_l";
					regulator-ramp-delay = <0x1771>;
					phandle = <0x0b>;

					regulator-state-mem {
						regulator-off-in-suspend;
					};
				};

				LDO_REG2 {
					regulator-max-microvolt = <0x1b7740>;
					regulator-boot-on;
					regulator-always-on;
					regulator-min-microvolt = <0x1b7740>;
					regulator-name = "vcc_1v8";

					regulator-state-mem {
						regulator-suspend-microvolt = <0x1b7740>;
						regulator-on-in-suspend;
					};
				};

				LDO_REG9 {
					regulator-max-microvolt = <0x325aa0>;
					regulator-boot-on;
					regulator-always-on;
					regulator-min-microvolt = <0x325aa0>;
					regulator-name = "vcc_sd";

					regulator-state-mem {
						regulator-suspend-microvolt = <0x325aa0>;
						regulator-on-in-suspend;
					};
				};

				SWITCH_REG1 {
					regulator-max-microvolt = <0x4c4b40>;
					regulator-boot-on;
					regulator-always-on;
					regulator-min-microvolt = <0x4c4b40>;
					regulator-name = "vcc5v0_usb";
					phandle = <0x82>;

					regulator-state-mem {
						regulator-off-in-suspend;
					};
				};

				LDO_REG7 {
					regulator-max-microvolt = <0x2dc6c0>;
					regulator-boot-on;
					regulator-always-on;
					regulator-min-microvolt = <0x2dc6c0>;
					regulator-name = "vcc_3v0";

					regulator-state-mem {
						regulator-off-in-suspend;
					};
				};

				DCDC_REG5 {
					regulator-max-microvolt = <0x2191c0>;
					regulator-boot-on;
					regulator-always-on;
					regulator-min-microvolt = <0x2191c0>;
					regulator-name = "vcc_buck5";
					phandle = <0x74>;

					regulator-state-mem {
						regulator-suspend-microvolt = <0x2191c0>;
						regulator-on-in-suspend;
					};
				};

				LDO_REG5 {
					regulator-max-microvolt = <0x16e360>;
					regulator-boot-on;
					regulator-always-on;
					regulator-min-microvolt = <0x16e360>;
					regulator-name = "vdd1v5_dvp";

					regulator-state-mem {
						regulator-off-in-suspend;
					};
				};

				DCDC_REG3 {
					regulator-boot-on;
					regulator-always-on;
					regulator-name = "vcc_ddr";

					regulator-state-mem {
						regulator-on-in-suspend;
					};
				};

				LDO_REG3 {
					regulator-max-microvolt = <0xdbba0>;
					regulator-boot-on;
					regulator-always-on;
					regulator-min-microvolt = <0xdbba0>;
					regulator-name = "vcc0v9_soc";

					regulator-state-mem {
						regulator-suspend-microvolt = <0xdbba0>;
						regulator-on-in-suspend;
					};
				};

				DCDC_REG1 {
					regulator-max-microvolt = <0x149970>;
					regulator-boot-on;
					regulator-always-on;
					regulator-min-microvolt = <0xb71b0>;
					regulator-name = "vdd_log";
					regulator-ramp-delay = <0x1771>;

					regulator-state-mem {
						regulator-suspend-microvolt = <0xdbba0>;
						regulator-on-in-suspend;
					};
				};

				LDO_REG1 {
					regulator-max-microvolt = <0xdbba0>;
					regulator-boot-on;
					regulator-always-on;
					regulator-min-microvolt = <0xdbba0>;
					regulator-name = "vcca_0v9";

					regulator-state-mem {
						regulator-off-in-suspend;
					};
				};

				SWITCH_REG2 {
					regulator-boot-on;
					regulator-always-on;
					regulator-name = "vcc3v3_s0";
					phandle = <0xab>;

					regulator-state-mem {
						regulator-off-in-suspend;
					};
				};

				LDO_REG8 {
					regulator-max-microvolt = <0x325aa0>;
					regulator-boot-on;
					regulator-always-on;
					regulator-min-microvolt = <0x1b7740>;
					regulator-name = "vccio_sd";

					regulator-state-mem {
						regulator-suspend-microvolt = <0x325aa0>;
						regulator-on-in-suspend;
					};
				};

				LDO_REG6 {
					regulator-max-microvolt = <0x16e360>;
					regulator-boot-on;
					regulator-always-on;
					regulator-min-microvolt = <0x16e360>;
					regulator-name = "vcc_1v5";

					regulator-state-mem {
						regulator-suspend-microvolt = <0x16e360>;
						regulator-on-in-suspend;
					};
				};
			};
		};

		tcs452x@10 {
			regulator-max-microvolt = <0x155cc0>;
			regulator-boot-on;
			pinctrl-0 = <0x77>;
			regulator-always-on;
			regulator-min-microvolt = <0xb3718>;
			regulator-name = "vdd_gpu";
			regulator-ramp-delay = <0x8fc>;
			fcs,suspend-voltage-selector = <0x01>;
			compatible = "tcs,tcs452x";
			status = "okay";
			reg = <0x10>;
			phandle = <0xa1>;
			vsel-gpios = <0x71 0x0e 0x00>;
			vin-supply = <0x73>;
			regulator-compatible = "fan53555-reg";

			regulator-state-mem {
				regulator-off-in-suspend;
			};
		};

		tcs452x@1c {
			regulator-max-microvolt = <0x16e360>;
			regulator-boot-on;
			pinctrl-0 = <0x76>;
			regulator-initial-state = <0x03>;
			regulator-always-on;
			regulator-min-microvolt = <0xadf34>;
			regulator-name = "vdd_cpu_b";
			regulator-ramp-delay = <0x8fc>;
			fcs,suspend-voltage-selector = <0x01>;
			compatible = "tcs,tcs452x";
			reg = <0x1c>;
			phandle = <0x0c>;
			vsel-gpios = <0x71 0x11 0x00>;
			vin-supply = <0x73>;
			regulator-compatible = "fan53555-reg";

			regulator-state-mem {
				regulator-off-in-suspend;
			};
		};
	};

	qos@ffab0000 {
		compatible = "rockchip,rk3399-qos\0syscon";
		reg = <0x00 0xffab0000 0x00 0x20>;
		phandle = <0x56>;
	};

	hdmi@ff940000 {
		power-domains = <0x16 0x15>;
		reg-io-width = <0x04>;
		clock-names = "iahb\0isfr\0vpll\0grf\0cec";
		interrupts = <0x00 0x17 0x04 0x00>;
		clocks = <0x08 0x174 0x08 0x71 0x08 0x07 0x08 0x16f 0x08 0x70>;
		#sound-dai-cells = <0x00>;
		compatible = "rockchip,rk3399-dw-hdmi";
		status = "disabled";
		rockchip,grf = <0x17>;
		reg = <0x00 0xff940000 0x00 0x20000>;
		phandle = <0x96>;

		ports {

			port {
				#address-cells = <0x01>;
				#size-cells = <0x00>;

				endpoint@1 {
					remote-endpoint = <0x98>;
					reg = <0x01>;
					phandle = <0x8a>;
				};

				endpoint@0 {
					remote-endpoint = <0x97>;
					reg = <0x00>;
					phandle = <0x90>;
				};
			};
		};
	};

	phy@ff800000 {
		power-domains = <0x16 0x09>;
		clock-names = "tcpdcore\0tcpdphy-ref";
		assigned-clocks = <0x08 0x80>;
		assigned-clock-rates = <0x2faf080>;
		resets = <0x08 0x9d 0x08 0x9c 0x08 0x14d>;
		clocks = <0x08 0x80 0x08 0x7f>;
		compatible = "rockchip,rk3399-typec-phy";
		status = "okay";
		rockchip,grf = <0x17>;
		reg = <0x00 0xff800000 0x00 0x40000>;
		reset-names = "uphy\0uphy-pipe\0uphy-tcphy";

		dp-port {
			#phy-cells = <0x00>;
			phandle = <0x2b>;
		};

		usb3-port {
			#phy-cells = <0x00>;
			phandle = <0x29>;
		};
	};

	binman {
		multiple-images;

		simple-bin {
			filename = "u-boot-rockchip.bin";
			pad-byte = <0xff>;

			u-boot-img {
				offset = <0x7f8000>;
			};

			blob {
				filename = "idbloader.img";
			};
		};
	};

	qos@ffaa8000 {
		compatible = "rockchip,rk3399-qos\0syscon";
		reg = <0x00 0xffaa8000 0x00 0x20>;
		phandle = <0x65>;
	};

	usbhub-reset {
		compatible = "usbhub-reset";
		uhrst-gpio = <0xae 0x15 0x00>;
	};

	aliases {
		i2c3 = "/i2c@ff130000";
		ethernet0 = "/ethernet@fe300000";
		i2c1 = "/i2c@ff110000";
		mmc1 = "/mmc@fe320000";
		i2c8 = "/i2c@ff3e0000";
		serial3 = "/serial@ff1b0000";
		pci0 = "/pcie@f8000000";
		i2c6 = "/i2c@ff150000";
		serial1 = "/serial@ff190000";
		i2c4 = "/i2c@ff3d0000";
		i2c2 = "/i2c@ff120000";
		spi1 = "/spi@ff1d0000";
		i2c0 = "/i2c@ff3c0000";
		serial4 = "/serial@ff370000";
		mmc0 = "/mmc@fe330000";
		i2c7 = "/i2c@ff160000";
		serial2 = "/serial@ff1a0000";
		i2c5 = "/i2c@ff140000";
		serial0 = "/serial@ff180000";
	};

	qos@ffac0080 {
		compatible = "rockchip,rk3399-qos\0syscon";
		reg = <0x00 0xffac0080 0x00 0x20>;
		phandle = <0x5a>;
	};

	usb@fe800000 {
		#address-cells = <0x02>;
		clock-names = "ref_clk\0suspend_clk\0bus_clk\0aclk_usb3_rksoc_axi_perf\0aclk_usb3\0grf_clk";
		resets = <0x08 0x125>;
		clocks = <0x08 0x81 0x08 0x83 0x08 0xf6 0x08 0xf8 0x08 0xf4 0x08 0xf9>;
		extcon = <0x24>;
		#size-cells = <0x02>;
		compatible = "rockchip,rk3399-dwc3";
		ranges;
		status = "okay";
		reset-names = "usb3-otg";

		usb@fe800000 {
			power-domains = <0x16 0x18>;
			snps,dis_enblslpm_quirk;
			phy-names = "usb2-phy\0usb3-phy";
			clock-names = "ref\0bus_early\0suspend";
			snps,dis-u2-freeclk-exists-quirk;
			phy_type = "utmi_wide";
			snps,dis_u2_susphy_quirk;
			interrupts = <0x00 0x69 0x04 0x00>;
			clocks = <0x08 0x81 0x08 0xf6 0x08 0x83>;
			compatible = "snps,dwc3";
			snps,dis-del-phy-power-chg-quirk;
			status = "okay";
			phys = <0x25 0x26>;
			reg = <0x00 0xfe800000 0x00 0x100000>;
			dr_mode = "otg";
			snps,dis-tx-ipgap-linecheck-quirk;
		};
	};

	qos@ffa60180 {
		compatible = "rockchip,rk3399-qos\0syscon";
		reg = <0x00 0xffa60180 0x00 0x20>;
	};

	usb@fe3c0000 {
		phy-names = "usb";
		interrupts = <0x00 0x1e 0x04 0x00>;
		clocks = <0x08 0x1ca 0x08 0x1cb 0x22>;
		compatible = "generic-ehci";
		status = "okay";
		phys = <0x23>;
		reg = <0x00 0xfe3c0000 0x00 0x20000>;
	};

	i2s@ff8a0000 {
		power-domains = <0x16 0x1c>;
		clock-names = "i2s_clk\0i2s_hclk";
		interrupts = <0x00 0x29 0x04 0x00>;
		clocks = <0x08 0x58 0x08 0x1d6>;
		dma-names = "tx\0rx";
		#sound-dai-cells = <0x00>;
		compatible = "rockchip,rk3399-i2s\0rockchip,rk3066-i2s";
		status = "disabled";
		reg = <0x00 0xff8a0000 0x00 0x1000>;
		phandle = <0x95>;
		dmas = <0x49 0x04 0x49 0x05>;
	};

	edp@ff970000 {
		power-domains = <0x16 0x19>;
		pinctrl-names = "default";
		pinctrl-0 = <0x9d>;
		clock-names = "dp\0pclk\0grf";
		resets = <0x08 0x11d>;
		interrupts = <0x00 0x0a 0x04 0x00>;
		clocks = <0x08 0x16a 0x08 0x16c 0x08 0x16f>;
		force-hpd;
		compatible = "rockchip,rk3399-edp";
		status = "okay";
		rockchip,grf = <0x17>;
		reg = <0x00 0xff970000 0x00 0x8000>;
		reset-names = "dp";

		ports {
			#address-cells = <0x01>;
			#size-cells = <0x00>;

			port@0 {
				#address-cells = <0x01>;
				#size-cells = <0x00>;
				reg = <0x00>;

				endpoint@1 {
					remote-endpoint = <0x9f>;
					reg = <0x01>;
					phandle = <0x89>;
				};

				endpoint@0 {
					remote-endpoint = <0x9e>;
					reg = <0x00>;
					phandle = <0x8e>;
				};
			};

			port@1 {
				#address-cells = <0x01>;
				#size-cells = <0x00>;
				reg = <0x01>;

				endpoint@0 {
					remote-endpoint = <0xa0>;
					reg = <0x00>;
					phandle = <0xac>;
				};
			};
		};
	};

	i2c@ff140000 {
		pinctrl-names = "default";
		#address-cells = <0x01>;
		pinctrl-0 = <0x31>;
		clock-names = "i2c\0pclk";
		assigned-clocks = <0x08 0x44>;
		assigned-clock-rates = <0xbebc200>;
		interrupts = <0x00 0x26 0x04 0x00>;
		clocks = <0x08 0x44 0x08 0x158>;
		#size-cells = <0x00>;
		compatible = "rockchip,rk3399-i2c";
		status = "disabled";
		reg = <0x00 0xff140000 0x00 0x1000>;
	};

	chosen {
		linux,uefi-mmap-size = <0xbe0>;
		bootargs = "Image root=PARTUUID=5602a318-bde2-40e1-87c2-a56c6650f128 rootwait rootfstype=ext4";
		linux,uefi-mmap-start = <0x00 0xb6ce3068>;
		kaslr-seed = <0x00 0x00>;
		linux,uefi-mmap-desc-size = <0x28>;
		u-boot,spl-boot-order = "same-as-spl\0/mmc@fe330000\0/mmc@fe320000";
		linux,uefi-mmap-desc-ver = <0x01>;
		u-boot,spl-boot-device = "/sdhci@fe330000";
		linux,uefi-system-table = <0x00 0xf7efbb80>;
		stdout-path = "serial2:1500000n8";
	};

	vop@ff900000 {
		power-domains = <0x16 0x11>;
		iommus = <0x8d>;
		clock-names = "aclk_vop\0dclk_vop\0hclk_vop";
		assigned-clocks = <0x08 0xd9 0x08 0x1d9>;
		u-boot,dm-pre-reloc;
		assigned-clock-rates = <0x17d78400 0x5f5e100>;
		resets = <0x08 0x112 0x08 0x116 0x08 0x118>;
		interrupts = <0x00 0x76 0x04 0x00>;
		clocks = <0x08 0xd9 0x08 0xb4 0x08 0x1d9>;
		compatible = "rockchip,rk3399-vop-big";
		status = "disabled";
		reg = <0x00 0xff900000 0x00 0x3efc>;
		reset-names = "axi\0ahb\0dclk";

		port {
			#address-cells = <0x01>;
			#size-cells = <0x00>;
			phandle = <0x0e>;

			endpoint@3 {
				remote-endpoint = <0x91>;
				reg = <0x03>;
				phandle = <0x9b>;
			};

			endpoint@1 {
				remote-endpoint = <0x8f>;
				reg = <0x01>;
				phandle = <0x99>;
			};

			endpoint@4 {
				remote-endpoint = <0x92>;
				reg = <0x04>;
				phandle = <0x2c>;
			};

			endpoint@2 {
				remote-endpoint = <0x90>;
				reg = <0x02>;
				phandle = <0x97>;
			};

			endpoint@0 {
				remote-endpoint = <0x8e>;
				reg = <0x00>;
				phandle = <0x9e>;
			};
		};
	};

	serial@ff190000 {
		reg-io-width = <0x04>;
		pinctrl-names = "default";
		pinctrl-0 = <0x35>;
		clock-names = "baudclk\0apb_pclk";
		interrupts = <0x00 0x62 0x04 0x00>;
		clocks = <0x08 0x52 0x08 0x161>;
		compatible = "rockchip,rk3399-uart\0snps,dw-apb-uart";
		status = "disabled";
		reg = <0x00 0xff190000 0x00 0x100>;
		reg-shift = <0x02>;
	};

	iommu@ff650800 {
		power-domains = <0x16 0x1f>;
		clock-names = "aclk\0iface";
		interrupts = <0x00 0x73 0x04 0x00>;
		clocks = <0x08 0xeb 0x08 0x1ea>;
		#iommu-cells = <0x00>;
		compatible = "rockchip,iommu";
		interrupt-names = "vpu_mmu";
		reg = <0x00 0xff650800 0x00 0x40>;
		phandle = <0x7f>;
	};

	qos@ffa5c000 {
		compatible = "rockchip,rk3399-qos\0syscon";
		reg = <0x00 0xffa5c000 0x00 0x20>;
		phandle = <0x5d>;
	};

	spi@ff1c0000 {
		pinctrl-names = "default";
		#address-cells = <0x01>;
		pinctrl-0 = <0x39 0x3a 0x3b 0x3c>;
		clock-names = "spiclk\0apb_pclk";
		interrupts = <0x00 0x44 0x04 0x00>;
		clocks = <0x08 0x47 0x08 0x15b>;
		#size-cells = <0x00>;
		dma-names = "tx\0rx";
		compatible = "rockchip,rk3399-spi\0rockchip,rk3066-spi";
		status = "disabled";
		reg = <0x00 0xff1c0000 0x00 0x1000>;
		dmas = <0x38 0x0a 0x38 0x0b>;
	};

	dma-controller@ff6d0000 {
		clock-names = "apb_pclk";
		interrupts = <0x00 0x05 0x04 0x00 0x00 0x06 0x04 0x00>;
		clocks = <0x08 0xd3>;
		arm,pl330-periph-burst;
		compatible = "arm,pl330\0arm,primecell";
		reg = <0x00 0xff6d0000 0x00 0x4000>;
		phandle = <0x49>;
		#dma-cells = <0x01>;
	};

	syscon@ff330000 {
		u-boot,dm-pre-reloc;
		compatible = "rockchip,rk3399-pmusgrf\0syscon";
		reg = <0x00 0xff330000 0x00 0xe3d4>;
	};

	external-gmac-clock {
		clock-output-names = "clkin_gmac";
		#clock-cells = <0x00>;
		clock-frequency = <0x7735940>;
		compatible = "fixed-clock";
		phandle = <0x18>;
	};

	pmu_a53 {
		interrupts = <0x01 0x07 0x08 0x0f>;
		compatible = "arm,cortex-a53-pmu";
	};

	isp0@ff910000 {
		power-domains = <0x16 0x13>;
		iommus = <0x93>;
		phy-names = "dphy";
		clock-names = "isp\0aclk\0hclk";
		interrupts = <0x00 0x2b 0x04 0x00>;
		clocks = <0x08 0x6e 0x08 0xe9 0x08 0x1e3>;
		compatible = "rockchip,rk3399-cif-isp";
		status = "disabled";
		phys = <0x94>;
		reg = <0x00 0xff910000 0x00 0x4000>;

		ports {
			#address-cells = <0x01>;
			#size-cells = <0x00>;

			port@0 {
				#address-cells = <0x01>;
				#size-cells = <0x00>;
				reg = <0x00>;
			};
		};
	};

	mipi@ff968000 {
		power-domains = <0x16 0x0f>;
		#address-cells = <0x01>;
		clock-names = "ref\0pclk\0phy_cfg\0grf";
		resets = <0x08 0xfc>;
		interrupts = <0x00 0x2e 0x04 0x00>;
		clocks = <0x08 0xa2 0x08 0x171 0x08 0xa4 0x08 0x16f>;
		#size-cells = <0x00>;
		compatible = "rockchip,rk3399-mipi-dsi\0snps,dw-mipi-dsi";
		status = "disabled";
		rockchip,grf = <0x17>;
		reg = <0x00 0xff968000 0x00 0x8000>;
		reset-names = "apb";

		ports {
			#address-cells = <0x01>;
			#size-cells = <0x00>;

			port@0 {
				#address-cells = <0x01>;
				#size-cells = <0x00>;
				reg = <0x00>;

				endpoint@1 {
					remote-endpoint = <0x9c>;
					reg = <0x01>;
					phandle = <0x8b>;
				};

				endpoint@0 {
					remote-endpoint = <0x9b>;
					reg = <0x00>;
					phandle = <0x91>;
				};
			};
		};
	};

	cpus {
		#address-cells = <0x02>;
		#size-cells = <0x00>;

		cpu@1 {
			capacity-dmips-mhz = <0x1e5>;
			cpu-supply = <0x0b>;
			clocks = <0x08 0x08>;
			cpu-idle-states = <0x09 0x0a>;
			device_type = "cpu";
			compatible = "arm,cortex-a53";
			dynamic-power-coefficient = <0x64>;
			reg = <0x00 0x01>;
			enable-method = "psci";
			phandle = <0x03>;
			#cooling-cells = <0x02>;
		};

		cpu@101 {
			capacity-dmips-mhz = <0x400>;
			cpu-supply = <0x0c>;
			clocks = <0x08 0x09>;
			cpu-idle-states = <0x09 0x0a>;
			device_type = "cpu";
			compatible = "arm,cortex-a72";
			dynamic-power-coefficient = <0x1b4>;
			reg = <0x00 0x101>;
			enable-method = "psci";
			phandle = <0x07>;
			#cooling-cells = <0x02>;
		};

		idle-states {
			entry-method = "psci";

			cluster-sleep {
				entry-latency-us = <0x190>;
				local-timer-stop;
				exit-latency-us = <0x1f4>;
				arm,psci-suspend-param = <0x1010000>;
				compatible = "arm,idle-state";
				phandle = <0x0a>;
				min-residency-us = <0x7d0>;
			};

			cpu-sleep {
				entry-latency-us = <0x78>;
				local-timer-stop;
				exit-latency-us = <0xfa>;
				arm,psci-suspend-param = <0x10000>;
				compatible = "arm,idle-state";
				phandle = <0x09>;
				min-residency-us = <0x384>;
			};
		};

		cpu-map {

			cluster0 {

				core3 {
					cpu = <0x05>;
				};

				core1 {
					cpu = <0x03>;
				};

				core2 {
					cpu = <0x04>;
				};

				core0 {
					cpu = <0x02>;
				};
			};

			cluster1 {

				core1 {
					cpu = <0x07>;
				};

				core0 {
					cpu = <0x06>;
				};
			};
		};

		cpu@2 {
			capacity-dmips-mhz = <0x1e5>;
			cpu-supply = <0x0b>;
			clocks = <0x08 0x08>;
			cpu-idle-states = <0x09 0x0a>;
			device_type = "cpu";
			compatible = "arm,cortex-a53";
			dynamic-power-coefficient = <0x64>;
			reg = <0x00 0x02>;
			enable-method = "psci";
			phandle = <0x04>;
			#cooling-cells = <0x02>;
		};

		cpu@0 {
			capacity-dmips-mhz = <0x1e5>;
			cpu-supply = <0x0b>;
			clocks = <0x08 0x08>;
			cpu-idle-states = <0x09 0x0a>;
			device_type = "cpu";
			compatible = "arm,cortex-a53";
			dynamic-power-coefficient = <0x64>;
			reg = <0x00 0x00>;
			enable-method = "psci";
			phandle = <0x02>;
			#cooling-cells = <0x02>;
		};

		cpu@100 {
			capacity-dmips-mhz = <0x400>;
			cpu-supply = <0x0c>;
			clocks = <0x08 0x09>;
			cpu-idle-states = <0x09 0x0a>;
			device_type = "cpu";
			compatible = "arm,cortex-a72";
			dynamic-power-coefficient = <0x1b4>;
			reg = <0x00 0x100>;
			enable-method = "psci";
			phandle = <0x06>;
			#cooling-cells = <0x02>;
		};

		cpu@3 {
			capacity-dmips-mhz = <0x1e5>;
			cpu-supply = <0x0b>;
			clocks = <0x08 0x08>;
			cpu-idle-states = <0x09 0x0a>;
			device_type = "cpu";
			compatible = "arm,cortex-a53";
			dynamic-power-coefficient = <0x64>;
			reg = <0x00 0x03>;
			enable-method = "psci";
			phandle = <0x05>;
			#cooling-cells = <0x02>;
		};
	};

	i2c@ff3d0000 {
		pinctrl-names = "default";
		#address-cells = <0x01>;
		pinctrl-0 = <0x78>;
		clock-names = "i2c\0pclk";
		assigned-clocks = <0x6a 0x0a>;
		assigned-clock-rates = <0xbebc200>;
		interrupts = <0x00 0x38 0x04 0x00>;
		clocks = <0x6a 0x0a 0x6a 0x1c>;
		#size-cells = <0x00>;
		compatible = "rockchip,rk3399-i2c";
		status = "disabled";
		reg = <0x00 0xff3d0000 0x00 0x1000>;
	};

	qos@ffac0000 {
		compatible = "rockchip,rk3399-qos\0syscon";
		reg = <0x00 0xffac0000 0x00 0x20>;
		phandle = <0x59>;
	};

	qos@ffa60100 {
		compatible = "rockchip,rk3399-qos\0syscon";
		reg = <0x00 0xffa60100 0x00 0x20>;
	};

	qos@ffab8000 {
		compatible = "rockchip,rk3399-qos\0syscon";
		reg = <0x00 0xffab8000 0x00 0x20>;
		phandle = <0x58>;
	};

	clock-controller@ff760000 {
		#reset-cells = <0x01>;
		assigned-clocks = <0x08 0x05 0x08 0x04 0x08 0x06 0x08 0xc0 0x08 0x1c0 0x08 0x140 0x08 0xc2 0x08 0x1c1 0x08 0x142 0x08 0xc9 0x08 0x1c2 0x08 0x143 0x08 0xe3 0x08 0xde 0x08 0x106 0x08 0x178>;
		u-boot,dm-pre-reloc;
		assigned-clock-rates = <0x2367b880 0x2faf0800 0x3b9aca00 0x8f0d180 0x47868c0 0x23c3460 0x5f5e100 0x5f5e100 0x2faf080 0x23c34600 0x5f5e100 0x2faf080 0x17d78400 0x17d78400 0xbebc200 0xbebc200>;
		#clock-cells = <0x01>;
		compatible = "rockchip,rk3399-cru";
		rockchip,grf = <0x17>;
		reg = <0x00 0xff760000 0x00 0x1000>;
		phandle = <0x08>;
	};

	vop@ff8f0000 {
		power-domains = <0x16 0x12>;
		iommus = <0x87>;
		clock-names = "aclk_vop\0dclk_vop\0hclk_vop";
		assigned-clocks = <0x08 0xdb 0x08 0x1db>;
		u-boot,dm-pre-reloc;
		assigned-clock-rates = <0x17d78400 0x5f5e100>;
		resets = <0x08 0x113 0x08 0x117 0x08 0x119>;
		interrupts = <0x00 0x77 0x04 0x00>;
		clocks = <0x08 0xdb 0x08 0xb5 0x08 0x1db>;
		compatible = "rockchip,rk3399-vop-lit";
		status = "disabled";
		reg = <0x00 0xff8f0000 0x00 0x3efc>;
		reset-names = "axi\0ahb\0dclk";

		port {
			#address-cells = <0x01>;
			#size-cells = <0x00>;
			phandle = <0x0d>;

			endpoint@3 {
				remote-endpoint = <0x8b>;
				reg = <0x03>;
				phandle = <0x9c>;
			};

			endpoint@1 {
				remote-endpoint = <0x89>;
				reg = <0x01>;
				phandle = <0x9f>;
			};

			endpoint@4 {
				remote-endpoint = <0x8c>;
				reg = <0x04>;
				phandle = <0x2d>;
			};

			endpoint@2 {
				remote-endpoint = <0x8a>;
				reg = <0x02>;
				phandle = <0x98>;
			};

			endpoint@0 {
				remote-endpoint = <0x88>;
				reg = <0x00>;
				phandle = <0x9a>;
			};
		};
	};

	qos@ffac8080 {
		compatible = "rockchip,rk3399-qos\0syscon";
		reg = <0x00 0xffac8080 0x00 0x20>;
		phandle = <0x68>;
	};

	serial@ff370000 {
		reg-io-width = <0x04>;
		pinctrl-names = "default";
		pinctrl-0 = <0x6f>;
		clock-names = "baudclk\0apb_pclk";
		interrupts = <0x00 0x66 0x04 0x00>;
		clocks = <0x6a 0x06 0x6a 0x22>;
		compatible = "rockchip,rk3399-uart\0snps,dw-apb-uart";
		status = "disabled";
		reg = <0x00 0xff370000 0x00 0x100>;
		reg-shift = <0x02>;
	};

	spdif@ff870000 {
		power-domains = <0x16 0x1c>;
		pinctrl-names = "default";
		pinctrl-0 = <0x84>;
		clock-names = "mclk\0hclk";
		interrupts = <0x00 0x42 0x04 0x00>;
		clocks = <0x08 0x55 0x08 0x1d7>;
		dma-names = "tx";
		#sound-dai-cells = <0x00>;
		compatible = "rockchip,rk3399-spdif";
		status = "disabled";
		reg = <0x00 0xff870000 0x00 0x1000>;
		dmas = <0x49 0x07>;
	};

	i2c@ff110000 {
		pinctrl-names = "default";
		#address-cells = <0x01>;
		pinctrl-0 = <0x2e>;
		clock-names = "i2c\0pclk";
		assigned-clocks = <0x08 0x41>;
		assigned-clock-rates = <0xbebc200>;
		interrupts = <0x00 0x3b 0x04 0x00>;
		clocks = <0x08 0x41 0x08 0x155>;
		#size-cells = <0x00>;
		compatible = "rockchip,rk3399-i2c";
		status = "disabled";
		reg = <0x00 0xff110000 0x00 0x1000>;
	};

	memory {
		device_type = "memory";
		reg = <0x00 0x200000 0x00 0xf7e00000>;
	};

	mmc@fe310000 {
		power-domains = <0x16 0x1c>;
		fifo-depth = <0x100>;
		clock-names = "biu\0ciu\0ciu-drive\0ciu-sample";
		resets = <0x08 0x79>;
		interrupts = <0x00 0x40 0x04 0x00>;
		clocks = <0x08 0x1ee 0x08 0x4d 0x08 0x9c 0x08 0x9d>;
		compatible = "rockchip,rk3399-dw-mshc\0rockchip,rk3288-dw-mshc";
		status = "disabled";
		reg = <0x00 0xfe310000 0x00 0x4000>;
		max-frequency = <0x8f0d180>;
		reset-names = "reset";
	};

	pwm@ff420030 {
		pinctrl-names = "default";
		pinctrl-0 = <0x7e>;
		clocks = <0x6a 0x1e>;
		#pwm-cells = <0x03>;
		compatible = "rockchip,rk3399-pwm\0rockchip,rk3288-pwm";
		status = "okay";
		reg = <0x00 0xff420030 0x00 0x10>;
		phandle = <0xad>;
	};

	pmu-clock-controller@ff750000 {
		#reset-cells = <0x01>;
		assigned-clocks = <0x6a 0x01>;
		u-boot,dm-pre-reloc;
		assigned-clock-rates = <0x284af100>;
		#clock-cells = <0x01>;
		compatible = "rockchip,rk3399-pmucru";
		rockchip,grf = <0x81>;
		reg = <0x00 0xff750000 0x00 0x1000>;
		phandle = <0x6a>;
	};

	qos@ffa90000 {
		compatible = "rockchip,rk3399-qos\0syscon";
		reg = <0x00 0xffa90000 0x00 0x20>;
		phandle = <0x62>;
	};

	qos@ffa60080 {
		compatible = "rockchip,rk3399-qos\0syscon";
		reg = <0x00 0xffa60080 0x00 0x20>;
	};
};
